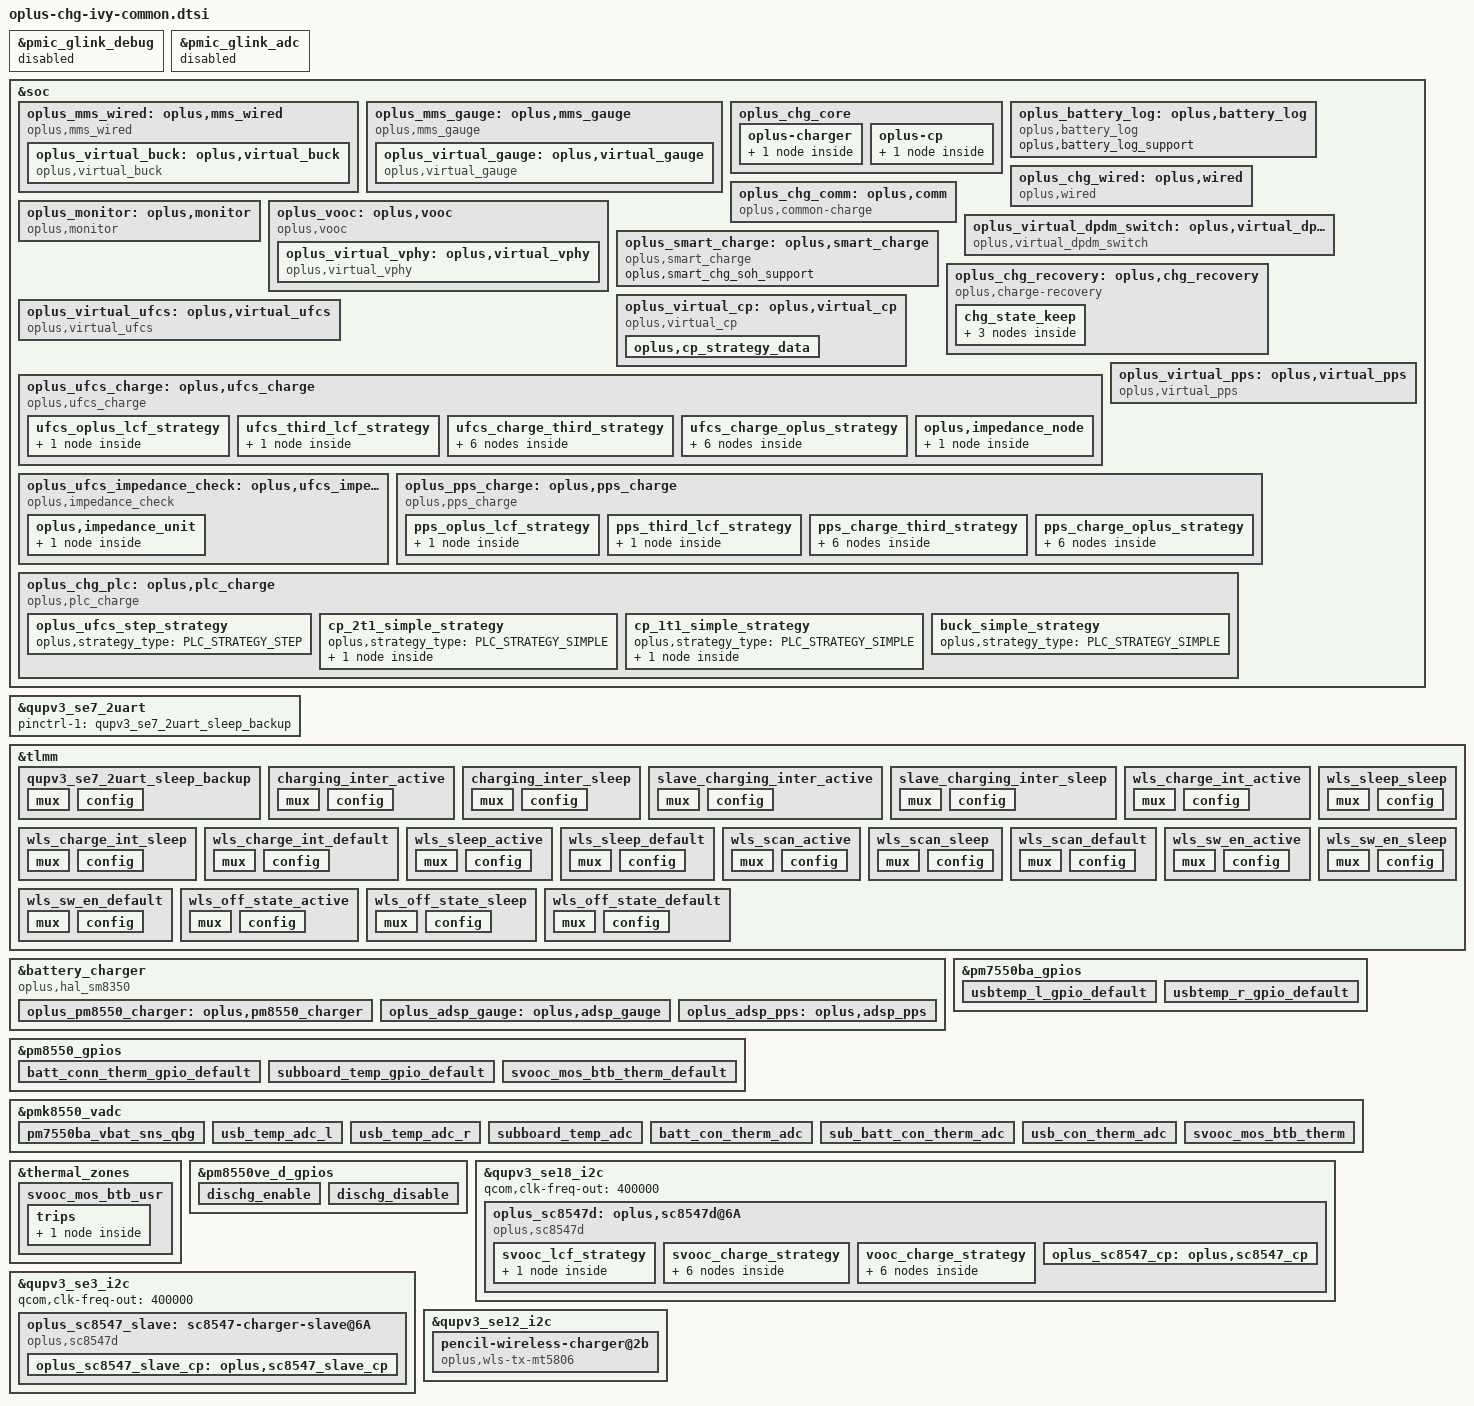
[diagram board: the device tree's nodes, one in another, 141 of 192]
//ifdef OPLUS_FEATURE_CHG_BASIC
//BSP.CHG.Basic, 2023/04/19, sjc Add for charging

#include "../oplus-chg-8850.h.dtsi"

/*
 * NOTICE:
 * sector 1: wired charging
 * sector 2: ufcs
 */

&pmic_glink_debug {
	status = "disabled";
};

&pmic_glink_adc {
	status = "disabled";
};

//#ifdef OPLUS_FEATURE_CHG_BASIC /* BSP.CHG.Basic, 2023/04/19, sjc Add for wired charging */
//for wired charging config
&soc {
	oplus_mms_wired: oplus,mms_wired {
		compatible = "oplus,mms_wired";
		oplus,buck_ic = <&oplus_virtual_buck>;

		oplus,adc_info_name = "855";

		/* BSP.CHG.Basic, 2024/09/27, Add for:
		High temperature long-term solution for Battery bulge from MTK*/
		high-temp-scheme;

		oplus,support_adjust_reverse_chg_cur;
		oplus,support_usbtemp_protect_v2;
		oplus_spec,usbtemp_batt_temp_low = <50>;
		oplus_spec,usbtemp_batt_temp_high = <50>;
		oplus_spec,usbtemp_batt_temp_over_hot = <60>;
		oplus_spec,usbtemp_ntc_temp_low = <57>;
		oplus_spec,usbtemp_ntc_temp_high = <69>;
		oplus_spec,usbtemp_temp_gap_low_with_batt_temp = <7>;
		oplus_spec,usbtemp_temp_gap_with_batt_temp_in_over_hot = <15>;
		oplus_spec,usbtemp_temp_gap_high_with_batt_temp = <12>;
		oplus_spec,usbtemp_temp_gap_low_without_batt_temp = <12>;
		oplus_spec,usbtemp_temp_gap_high_without_batt_temp = <24>;
		oplus_spec.usbtemp_rise_fast_temp_low = <3>;
		oplus_spec.usbtemp_rise_fast_temp_high = <3>;
		oplus_spec.usbtemp_rise_fast_temp_count_low = <30>;
		oplus_spec.usbtemp_rise_fast_temp_count_high = <20>;
		oplus_spec,usbtemp_cool_down_ntc_low = <54>;
		oplus_spec,usbtemp_cool_down_ntc_high = <65>;
		oplus_spec,usbtemp_cool_down_gap_low = <12>;
		oplus_spec,usbtemp_cool_down_gap_high = <20>;
		oplus_spec,usbtemp_cool_down_recover_ntc_low = <48>;
		oplus_spec,usbtemp_cool_down_recover_ntc_high = <60>;
		oplus_spec,usbtemp_cool_down_recover_gap_low = <6>;
		oplus_spec,usbtemp_cool_down_recover_gap_high = <15>;
		oplus_spec,otg_output = <2000 3600
					 1500 2900>;

		oplus_virtual_buck: oplus,virtual_buck {
			compatible = "oplus,virtual_buck";
			oplus,buck_ic = <&oplus_pm8550_charger>;
			oplus,buck_ic_index = <0>;
			oplus,buck_ic_connect = <OPLUS_CHG_IC_CONNECT_PARALLEL>;
			oplus,main_charger = <0>;
			oplus,buck_ic_current_ratio = <100>;
			oplus,buck_ic_func_group = <&plat_pm8550_groups>;

			oplus,ic_type = <OPLUS_CHG_IC_VIRTUAL_BUCK>;
			oplus,ic_index = <0>;

			oplus,dischg-gpio = <&pm8550ve_d_gpios 5 0x00>;
			oplus,usbtemp_conversion_ratio = <10>;

			pinctrl-names = "usbtemp_l_gpio_default", "usbtemp_r_gpio_default",
						"dischg_enable", "dischg_disable";
			pinctrl-0 = <&usbtemp_l_gpio_default>;
			pinctrl-1 = <&usbtemp_r_gpio_default>;
			pinctrl-2 = <&dischg_enable>;
			pinctrl-3 = <&dischg_disable>;

			io-channels = <&pmk8550_vadc PM7550BA_ADC5_GEN3_AMUX2_GPIO2_100K_PU>,
					<&pmk8550_vadc PM7550BA_ADC5_GEN3_AMUX_THM6_GPIO6_100K_PU>;
			io-channel-names = "usb_temp_adc_l", "usb_temp_adc_r";

			oplus,uart_tx-gpio = <&tlmm 62 0x00>;
			oplus,uart_rx-gpio = <&tlmm 63 0x00>;
		};
	};

	oplus_mms_gauge: oplus,mms_gauge {
		compatible = "oplus,mms_gauge";
		oplus,gauge_ic = <&oplus_virtual_gauge>;
		oplus,topic-update-interval = <5000>;
		oplus,support_subboard_ntc;
		oplus,fcl_support;
		oplus,fcl_index = <1>;	/* Platform gauge */
		oplus,vb_offset = <20>;
		oplus,voocphy_ic = <&oplus_virtual_vphy>;

		oplus_virtual_gauge: oplus,virtual_gauge {
			compatible = "oplus,virtual_gauge";
			oplus,batt_capacity_mah = <8000>;
			oplus,ic_type = <OPLUS_CHG_IC_VIRTUAL_GAUGE>;
			oplus,ic_index = <0>;
		};
	};
};

&soc {
	oplus_chg_core: oplus_chg_core {
		oplus,chg_framework_v2;
		oplus,battery_type_by_smem;
		oplus,smart_charging_screenoff;
		oplus,chg_spec_version = <OPLUS_CHG_SPEC_VER_V3P7>;
		oplus,common-charge-icl-support;
		oplus,boot_reset_adapter_support;

		oplus-charger {
			plat_pm8550_groups: oplus,plat_pm8550-groups {
				functions = <
					OPLUS_IC_FUNC_INIT
					OPLUS_IC_FUNC_EXIT
					OPLUS_IC_FUNC_REG_DUMP
					OPLUS_IC_FUNC_SMT_TEST
					OPLUS_IC_FUNC_BUCK_INPUT_PRESENT
					OPLUS_IC_FUNC_BUCK_INPUT_SUSPEND
					OPLUS_IC_FUNC_BUCK_INPUT_IS_SUSPEND
					OPLUS_IC_FUNC_BUCK_OUTPUT_SUSPEND
					OPLUS_IC_FUNC_BUCK_OUTPUT_IS_SUSPEND
					OPLUS_IC_FUNC_BUCK_GET_CC_ORIENTATION
					OPLUS_IC_FUNC_BUCK_GET_CHARGER_TYPE
					OPLUS_IC_FUNC_BUCK_RERUN_BC12
					OPLUS_IC_FUNC_BUCK_QC_DETECT_ENABLE
					OPLUS_IC_FUNC_BUCK_SHIPMODE_ENABLE
					OPLUS_IC_FUNC_BUCK_SET_QC_CONFIG
					OPLUS_IC_FUNC_BUCK_SET_PD_CONFIG
					OPLUS_IC_FUNC_GET_SHUTDOWN_SOC
					OPLUS_IC_FUNC_BACKUP_SOC
					OPLUS_IC_FUNC_GET_TYPEC_MODE
					OPLUS_IC_FUNC_BUCK_SET_ICL
					OPLUS_IC_FUNC_BUCK_GET_ICL
					OPLUS_IC_FUNC_BUCK_SET_FCC
					OPLUS_IC_FUNC_BUCK_SET_FV
					OPLUS_IC_FUNC_BUCK_SET_ITERM
					OPLUS_IC_FUNC_BUCK_SET_RECHG_VOL
					OPLUS_IC_FUNC_BUCK_GET_INPUT_CURR
					OPLUS_IC_FUNC_BUCK_GET_INPUT_VOL
					OPLUS_IC_FUNC_GET_CHARGER_CYCLE
					OPLUS_IC_FUNC_OTG_BOOST_ENABLE
					OPLUS_IC_FUNC_SET_OTG_BOOST_CURR_LIMIT
					OPLUS_IC_FUNC_BUCK_GET_VBUS_COLLAPSE_STATUS
					OPLUS_IC_FUNC_GET_OTG_ENABLE
					OPLUS_IC_FUNC_SET_OTG_SWITCH_STATUS
					OPLUS_IC_FUNC_GET_OTG_SWITCH_STATUS
					OPLUS_IC_FUNC_GET_OTG_ONLINE_STATUS
					OPLUS_IC_FUNC_BUCK_GET_HW_DETECT
					OPLUS_IC_FUNC_VOOCPHY_SET_MATCH_TEMP
					OPLUS_IC_FUNC_IS_OPLUS_SVID
					OPLUS_IC_FUNC_BUCK_SET_VINDPM
					OPLUS_IC_FUNC_WLS_BOOST_ENABLE
					OPLUS_IC_FUNC_SET_WLS_BOOST_VOL
					OPLUS_IC_FUNC_SET_WLS_BOOST_CURR_LIMIT
					OPLUS_IC_FUNC_BUCK_WLS_INPUT_SUSPEND
					OPLUS_IC_FUNC_BUCK_SET_WLS_ICL
					OPLUS_IC_FUNC_BUCK_GET_WLS_ICL
					OPLUS_IC_FUNC_BUCK_GET_WLS_INPUT_CURR
					OPLUS_IC_FUNC_BUCK_GET_WLS_INPUT_VOL
					OPLUS_IC_FUNC_BUCK_WLS_AICL_ENABLE
					OPLUS_IC_FUNC_BUCK_WLS_AICL_RERUN
					OPLUS_IC_FUNC_BUCK_DIS_INSERT_DETECT
					OPLUS_IC_FUNC_GET_TYPEC_ROLE
					OPLUS_IC_FUNC_SET_TYPEC_MODE
					OPLUS_IC_FUNC_BUCK_GET_USB_BTB_TEMP
					OPLUS_IC_FUNC_BUCK_GET_BATT_BTB_TEMP
					OPLUS_IC_FUNC_BUCK_GET_TYPEC_STATE
					OPLUS_IC_FUNC_BUCK_SET_CHG_PATH
					OPLUS_IC_FUNC_BUCK_GET_CHG_PATH_STATUS
					OPLUS_IC_FUNC_BUCK_GET_USB_AICL_ENHANCE
					OPLUS_IC_FUNC_BUCK_SET_AICL_POINT
					OPLUS_IC_FUNC_BUCK_GET_POWER_ROLE
					OPLUS_IC_FUNC_BUCK_ITEM_CHECK
					OPLUS_IC_FUNC_BUCK_GET_CC_STATE
				>;
				virqs = <
					OPLUS_IC_VIRQ_ERR
					OPLUS_IC_VIRQ_CC_DETECT
					OPLUS_IC_VIRQ_PLUGIN
					OPLUS_IC_VIRQ_CC_CHANGED
					OPLUS_IC_VIRQ_SUSPEND_CHECK
					OPLUS_IC_VIRQ_CHG_TYPE_CHANGE
					OPLUS_IC_VIRQ_OTG_ENABLE
					OPLUS_IC_VIRQ_SVID
					OPLUS_IC_VIRQ_TYPEC_STATE
					OPLUS_IC_VIRQ_POWER_ROLE_STATE
				>;
			};
		};

		oplus-cp {
			sc8547_cp_groups: oplus,cp_groups {
				functions = <
					OPLUS_IC_FUNC_INIT
					OPLUS_IC_FUNC_EXIT
					OPLUS_IC_FUNC_REG_DUMP
					OPLUS_IC_FUNC_SMT_TEST
					OPLUS_IC_FUNC_CP_ENABLE
					OPLUS_IC_FUNC_CP_HW_INTI
					OPLUS_IC_FUNC_CP_SET_WORK_MODE
					OPLUS_IC_FUNC_CP_GET_WORK_MODE
					OPLUS_IC_FUNC_CP_CHECK_WORK_MODE_SUPPORT
					OPLUS_IC_FUNC_CP_SET_IIN
					OPLUS_IC_FUNC_CP_GET_VIN
					OPLUS_IC_FUNC_CP_GET_IIN
					OPLUS_IC_FUNC_CP_GET_VOUT
					OPLUS_IC_FUNC_CP_GET_IOUT
					OPLUS_IC_FUNC_CP_GET_VAC
					OPLUS_IC_FUNC_CP_SET_WORK_START
					OPLUS_IC_FUNC_CP_GET_WORK_STATUS
					OPLUS_IC_FUNC_CP_SET_ADC_ENABLE
					OPLUS_IC_FUNC_CP_WATCHDOG_ENABLE
					OPLUS_IC_FUNC_CP_SET_UCP_DISABLE
					OPLUS_IC_FUNC_CP_GET_IIN_MAX
					OPLUS_IC_FUNC_CP_WATCHDOG_RESET
					OPLUS_IC_FUNC_CP_SET_SSTIMEOUT_UCP_ENABLE
				>;
				virqs = <
					OPLUS_IC_VIRQ_ERR
					OPLUS_IC_VIRQ_ONLINE
					OPLUS_IC_VIRQ_OFFLINE
				>;
			};
		};
	};
};

&qupv3_se7_2uart {
	pinctrl-1 = <&qupv3_se7_2uart_sleep_backup>;
	status = "okay";
};

&tlmm {
	qupv3_se7_2uart_sleep_backup:qupv3_se7_2uart_sleep_backup {
		mux {
			pins = "gpio62", "gpio63";
			function = "gpio";
		};

		config {
			pins = "gpio62", "gpio63";
			drive-strength = <2>;
			bias-disable;
			input-enable;
		};
	};

	charging_inter_active: charging_inter_active {
		mux {
			pins = "gpio61";
			function = "gpio";
		};
		config {
			pins = "gpio61";
			bias-pull-up;
			drive-strength = <2>;
			input-enable;
		};
	};

	charging_inter_sleep: charging_inter_sleep {
		mux {
			pins = "gpio61";
			function = "gpio";
		};
		config {
			pins = "gpio61";
			bias-pull-up;
			drive-strength = <2>;
			input-enable;
		};
	};

	slave_charging_inter_active: slave_charging_inter_active {
		mux {
			pins = "gpio28";
			function = "gpio";
		};
		config {
			pins = "gpio28";
			bias-pull-up;
			drive-strength = <2>;
			input-enable;
		};
	};

	slave_charging_inter_sleep: slave_charging_inter_sleep {
		mux {
			pins = "gpio28";
			function = "gpio";
		};
		config {
			pins = "gpio28";
			bias-pull-up;
			drive-strength = <2>;
			input-enable;
		};
	};
};

&battery_charger {
	compatible = "oplus,hal_sm8350";
	oplus,chg_ops = "plat-pmic";

	qcom,pmic_ftm_vph = "/sys/bus/spmi/drivers/pmic-spmi/0-00/c426000.spmi:pmk8850@0:vadc@9000/iio:device0/in_voltage_pmih010x_vph2_pwr_input";
	qcom,pmic_ftm_vbat = "/sys/bus/spmi/drivers/pmic-spmi/0-00/c426000.spmi:pmk8850@0:vadc@9000/iio:device0/in_voltage_pmih010x_vbat_sns_qbg_input";

	pinctrl-names = "default", "subboard_temp_gpio_default";
	pinctrl-0 = <&svooc_mos_btb_therm_default>,
			<&batt_conn_therm_gpio_default>;
	pinctrl-1 = <&subboard_temp_gpio_default>;

	oplus,usb_aicl_enhance;
	oplus,voocphy_support;
	oplus,vooc_project = <14>;
	oplus,batt_num = <1>;
	oplus,otg_scheme = <0>;//0:cid 1:ccdetect_gpio 2:switch
	oplus,ufcs_run_check_support;
	oplus,soccp_support;
	io-channels	= <&pmk8550_vadc PM8550_ADC5_GEN3_AMUX2_GPIO4_100K_PU>,
			  <&pmk8550_vadc PM8550_ADC5_GEN3_AMUX_THM6_GPIO2_100K_PU>,
			  <&pmk8550_vadc PM7550BA_ADC5_GEN3_AMUX_THM4_USB_THERM_100K_PU>,
			  <&pmk8550_vadc PM7550BA_ADC5_GEN3_VPH_PWR>,
			  <&pmk8550_vadc PM7550BA_ADC5_GEN3_VBAT_SNS_QBG>;
	io-channel-names = "subboard_temp_adc",
			   "batt_con_therm_adc",
			   "usb_con_therm_adc",
			   "vph_pwr",
			   "vbat_sns_qbg";

	oplus_pm8550_charger: oplus,pm8550_charger {
		oplus,ic_type = <OPLUS_CHG_IC_BUCK>;
		oplus,ic_index = <0>;
	};
	oplus_adsp_gauge: oplus,adsp_gauge {
		oplus,ic_type = <OPLUS_CHG_IC_GAUGE>;
		oplus,ic_index = <0>;
		oplus,ic_devinfo = "QBG","Qcom";
	};
	oplus_adsp_pps: oplus,adsp_pps {
		oplus,ic_type = <OPLUS_CHG_IC_PPS>;
		oplus,ic_index = <0>;
	};
};

&soc {
	oplus_battery_log: oplus,battery_log {
		compatible = "oplus,battery_log";
		oplus,battery_log_support;
	};

	oplus_chg_wired: oplus,wired {
		compatible = "oplus,wired";

		oplus,vooc-support;
		oplus,qc-curr-check-support;
		oplus_spec,vbatt_pdqc_to_5v_thr = <4500>;
		oplus_spec,vbatt_pdqc_to_9v_thr = <4500>;
		oplus_spec,pd-iclmax-ma = <2000>;
		oplus_spec,qc-iclmax-ma = <2000>;
		oplus_spec,non-standard-ibatmax-ma = <500>;
		oplus_spec,input-power-mw = <
			2500		/* OPLUS_WIRED_CHG_MODE_UNKNOWN */
			2500		/* OPLUS_WIRED_CHG_MODE_SDP */
			7500		/* OPLUS_WIRED_CHG_MODE_CDP */
			10000		/* OPLUS_WIRED_CHG_MODE_DCP */
			30000		/* OPLUS_WIRED_CHG_MODE_VOOC */
			13500		/* OPLUS_WIRED_CHG_MODE_QC */
			13500		/* OPLUS_WIRED_CHG_MODE_PD */
		>;
		oplus_spec,led_on-fccmax-ma = <0 1173 3300 3300 3300 3300 3300 1000 0>;
		oplus_spec,fccmax-ma-lv = <
			0 1173 2200 2200 2200 2200 2200 2200 0	/* OPLUS_WIRED_CHG_MODE_UNKNOWN */
			0 600 600  600  600  600  600  600 0	/* OPLUS_WIRED_CHG_MODE_SDP */
			0 1173 1600 1600 1600 1600 1600 1600 0	/* OPLUS_WIRED_CHG_MODE_CDP */
			0 1173 2200 2200 2200 2200 2200 2200 0	/* OPLUS_WIRED_CHG_MODE_DCP */
			0 1173 3300 3300 3300 3300 3300 3300 0	/* OPLUS_WIRED_CHG_MODE_VOOC */
			0 1173 3300 3300 3300 3300 3300 3300 0	/* OPLUS_WIRED_CHG_MODE_QC */
			0 1173 3300 3300 3300 3300 3300 3300 0	/* OPLUS_WIRED_CHG_MODE_PD */
		>;
		oplus_spec,fccmax-ma-hv = <
			0 1173 2200 2200 2200 2200 2200 2200 0	/* OPLUS_WIRED_CHG_MODE_UNKNOWN */
			0 600  600  600  600  600  600  600 0	/* OPLUS_WIRED_CHG_MODE_SDP */
			0 1173 1600 1600 1600 1600 1600 1600 0	/* OPLUS_WIRED_CHG_MODE_CDP */
			0 1173 2200 2200 2200 2200 2200 2200 0	/* OPLUS_WIRED_CHG_MODE_DCP */
			0 1173 3300 3300 3300 3300 3300 3300 0	/* OPLUS_WIRED_CHG_MODE_VOOC */
			0 1173 3300 3300 3300 3300 3300 3300 0	/* OPLUS_WIRED_CHG_MODE_QC */
			0 1173 3300 3300 3300 3300 3300 3300 0	/* OPLUS_WIRED_CHG_MODE_PD */
		>;

		oplus_spec,cool_down_sale_pdqc_vol_mv = <5000>;
		oplus_spec,cool_down_sale_pdqc_curr_ma = <1200>;
		oplus_spec,cool_down_pdqc_vol_mv = <5000 5000 5000 9000>;
		oplus_spec,cool_down_pdqc_curr_ma = <1200 1500 2000 1500>;
		oplus_spec,cool_down_vooc_curr_ma = <1200 1500 2000 2500 3000 3000>;
		oplus_spec,cool_down_normal_curr_ma = <1200 1500 2000>;

		oplus_spec,vbus_ov_thr_mv = <11000 11000>;
		oplus_spec,vbus_uv_thr_mv = <4300 4300>;

		/* first data is strategy used temp type */
		oplus,vooc_strategy_name = "cgcl";
		oplus,vooc_strategy_data = <OPLUS_STRATEGY_USE_BATT_TEMP
					    0   420 6000 1 0
					    415 430 3000 2 0
					    425 440 2000 2 1>;
	};

	oplus_chg_comm: oplus,comm {
		compatible = "oplus,common-charge";
		oplus_spec,dec_step = <20>;
		oplus_spec,dec-vol-cc-full-thr = <0 200 400 600 800 1000>;
		oplus_spec,dec-vol-fv-full-mv = <0 0 20 20 40 40>;

		oplus_spec,batt-them-thr = <(-100) 0 50 120 160 350 450 530>;
		oplus_spec,iterm-ma = <401>;
		oplus_spec,fv-mv = <4490 4490 4490 4490 4490 4490 4470 4130 4130>;
		oplus_spec,sw-fv-mv = <4440 4440 4440 4440 4440 4440 4420 4080 4080>;
		oplus_spec,hw-fv-inc-mv = <0 18 18 18 18 18 18 18 0>;
		oplus_spec,sw-over-fv-mv = <4500 4500 4500 4500 4500 4500 4480 4140 4140>;
		oplus_spec,sw-over-fv-dec-mv = <8>;
		oplus_spec,non-standard-sw-fv-mv = <3930>;
		oplus_spec,non-standard-fv-mv = <3980>;
		oplus_spec,non-standard-hw-fv-inc-mv = <18>;
		oplus_spec,non-standard-sw-over-fv-mv = <3990>;
		oplus_spec,non-standard-vbatdet-mv = <3680>;
		oplus_spec,wired-vbatdet-mv = <0 4190 4290 4390 4390 4390 4370 4030 0>;
		oplus_spec,wls-vbatdet-mv = <0 4190 4290 4390 4390 4390 4370 4030 0>;
		oplus_spec,fcc-gear-thr-mv = <4180>;
		oplus_spec,fcc-gear-shake-mv = <400 400 400 300 300 180 180 180 180>;
		oplus_spec,vbatt-ov-thr-mv = <4600>;
		oplus_spec,full_pre_ffc_judge;
		oplus_spec,full-pre-ffc-mv = <4485>;
		oplus_spec,ffc-temp-thr = <120 210 350 440>;
		oplus_spec,wired-ffc-step-max = <2>;
		oplus_spec,wired-ffc-fv-mv = <4630 4630>;

		oplus_spec,wired-ffc-fv-cutoff-mv = <4545 4545 4500
						     4545 4545 4483>;

		oplus_spec,removed_bat_decidegc = <390>;

		oplus_spec,wired-ffc-fcc-ma = <2076 2076 1500
					       1976  1976  1000>;
		oplus_spec,wired-ffc-fcc-cutoff-ma = <1876 1876 1300
						      1776 1776 900>;

		oplus_spec,drop_soc_2_temp_ladder = <(-50) 0 0 0 0 0 0 0 0 0>;
		oplus_spec,volt_diff_ladder_of_drop_soc_2 = <80 80 0 0 0 0 0 0 0 0>;
		oplus_spec,keep_soc_2_temp_ladder = <(-200) (-50) 0 0 0 0 0 0 0 0>;
		oplus_spec,volt_diff_ladder_of_keep_soc_2 = <10 20 30 0 0 0 0 0 0 0>;
		oplus_spec,back_rm_of_drop_soc_2 = <36>;
		oplus_spec,back_rm_of_drop_soc_1 = <0>;
		oplus_spec,load_current_of_drop_soc_2 = <1500>;
		oplus_spec,load_current_of_drop_soc_1 = <2000>;
		oplus_spec,current_limit_of_drop_soc_2 = <350>;
		oplus_spec,volt_of_fast_drop_soc_1 = <3300>;
		oplus_spec,support_uisoc_low_battery_control;

		oplus_spec,vbat_uv_thr_mv = <3300>;
		oplus_spec,vbat_charging_uv_thr_mv = <3200>;

		/*If use subboard NTC as battery temp, config it as 20, otherwise 0 */
		oplus_spec,tbatt_power_off_cali_temp = <0>;
		oplus,vooc_show_ui_soc_decimal;
		oplus_spec,poweroff_high_batt_temp = <720>;
		oplus_spec,poweroff_emergency_batt_temp = <770>;
		oplus,ui_soc_decimal_speedmin = <20>;

		oplus,gauge_stuck_jump_support;
		oplus,gauge_stuck_threshold = <15>;
		oplus,gauge_stuck_time = <50>;

		oplus,ui_soc_2_voltage_comp_mv = <30>;
		oplus,chg_shutdown_max_mv = <3200>;

		oplus_spec,hw_iterm_support;
		oplus,pm_power_off_with_hightemp;
	};

	oplus_monitor: oplus,monitor {
		compatible = "oplus,monitor";
		oplus,topic-update-interval = <60000>;

		track,fast_chg_break_t_thd = <2500>;
		track,general_chg_break_t_thd = <300>;
		track,voocphy_type = <TRACK_AP_DUAL_CP_VOOCPHY>;
		track,wired_max_power = <67000>;
		track,wired_fast_chg_scheme = <TRACK_WIRED_SCHEME_SINGLE_60W_67W>;
		track,track_ver = <TRACK_VER_4_0>;
	};

	oplus_vooc: oplus,vooc {
		compatible = "oplus,vooc";
		oplus,vooc_ic = <&oplus_virtual_vphy>;

		oplus,vooc_data_width = <7>;
		oplus,vooc_curr_max = <CP_CURR_LIMIT_7BIT_12_6A>;
		oplus,vooc_project = <VOOC_PROJECT_11V6P1A_SINGLE_BAT_SVOOC>;
		oplus,vooc_curr_table_type = <VOOC_CP_CURR_TABLE>;
		oplus,vooc_power_max_w = <67>;
		oplus,voocphy_support = <AP_DUAL_CP_VOOCPHY>;
		oplus,subboard_ntc_abnormal_current = <4000>;
		oplus,support_fake_vooc_check;
		oplus,cp_cooldown_limit_percent_75 = <CP_CURR_LIMIT_7BIT_6_0A>;
		oplus,cp_cooldown_limit_percent_85 = <CP_CURR_LIMIT_7BIT_4_0A>;

		oplus,general_strategy_name = "cgcl";
		oplus,general_strategy_data = < OPLUS_STRATEGY_USE_SHELL_TEMP
						0   380 CP_CURR_LIMIT_7BIT_12_6A 1 0
						370 400 CP_CURR_LIMIT_7BIT_7_0A 2 0
						390 420 CP_CURR_LIMIT_7BIT_5_0A 3 1
						410 430 CP_CURR_LIMIT_7BIT_4_0A 4 2
						420 440 CP_CURR_LIMIT_7BIT_3_0A 4 3 >;
		oplus,plc_strategy-data = <&buck_simple_strategy &cp_2t1_simple_strategy &cp_1t1_simple_strategy>;
		oplus,plc_strategy-names = "default", "svooc", "vooc";

		oplus_virtual_vphy: oplus,virtual_vphy {
			compatible = "oplus,virtual_vphy";
			oplus,vphy_ic = <&oplus_sc8547d>;
			oplus,dpdm_switch_ic = <&oplus_virtual_dpdm_switch>;

			oplus,ic_type = <OPLUS_CHG_IC_VIRTUAL_VPHY>;
			oplus,ic_index = <0>;
		};
	};

	oplus_virtual_dpdm_switch: oplus,virtual_dpdm_switch {
		compatible = "oplus,virtual_dpdm_switch";
		oplus,ic_type = <OPLUS_CHG_IC_MISC>;
		oplus,ic_index = <0>;
		oplus,use_audio_switch;
	};

	oplus_smart_charge: oplus,smart_charge {
		compatible = "oplus,smart_charge";
		oplus,smart_chg_soh_support;
	};

	oplus_chg_recovery: oplus,chg_recovery {
		compatible = "oplus,charge-recovery";

		chg_state_keep {
			wired_disconnect_detection {
				protocol_switch_table = <
					CHG_PROTOCOL_UFCS  44  3  3
					CHG_PROTOCOL_PPS    0  3  3
					CHG_PROTOCOL_VOOC   0  0  0
					CHG_PROTOCOL_PD     0  3  3
					CHG_PROTOCOL_QC     0  3  3
					CHG_PROTOCOL_BC12   0  3  3
				>;
			};
			vooc_disconnect_detection {};
			dcp_disconnect_detection {};
		};
	};
};

&pm7550ba_gpios {
	usbtemp_l_gpio_default: usbtemp_l_gpio_default {
		pins = "gpio6"; //GPIO 6
		function = "normal"; //normal
		bias-high-impedance; //DISABLE for ADC
		bias-disable;
	};
	usbtemp_r_gpio_default: usbtemp_r_gpio_default {
		pins = "gpio18"; //GPIO 18
		function = "normal"; //normal
		bias-high-impedance; //DISABLE for ADC
		bias-disable;
	};
};

&pm8550_gpios {
	batt_conn_therm_gpio_default: batt_conn_therm_gpio_default {
		pins = "gpio2";
		function = "normal";
		bias-high-impedance;
		bias-disable;
		output-disable;
	};

	subboard_temp_gpio_default: subboard_temp_gpio_default {
		pins = "gpio4";
		function = "normal";
		bias-high-impedance;
		bias-disable;
	};

	svooc_mos_btb_therm_default: svooc_mos_btb_therm_default {
		pins = "gpio7";
		function = "normal";
		bias-high-impedance;
		bias-disable;
	};
};

&pmk8550_vadc {
	pm7550ba_vbat_sns_qbg {
		reg = <PM7550BA_ADC5_GEN3_VBAT_SNS_QBG>;
		label = "pm7550ba_vbat_sns_qbg";
		qcom,pre-scaling = <1 3>;
	};

	usb_temp_adc_l {
		reg = <PM7550BA_ADC5_GEN3_AMUX2_GPIO2_100K_PU>;
		label = "usb_temp_adc_l";
		qcom,pre-scaling = <1 1>;
		qcom,hw-settle-time = <200>;
		qcom,scale-fn-type = <OPLUS_ADC_SCALE_HW_CALIB_DEFAULT>;
	};

	/delete-node/ pm7550ba_sys_therm_4;

	usb_temp_adc_r {
		reg = <PM7550BA_ADC5_GEN3_AMUX_THM6_GPIO6_100K_PU>;
		label = "usb_temp_adc_r";
		qcom,pre-scaling = <1 1>;
		qcom,hw-settle-time = <200>;
		qcom,scale-fn-type = <OPLUS_ADC_SCALE_HW_CALIB_DEFAULT>;
	};

	subboard_temp_adc {
		reg = <PM8550_ADC5_GEN3_AMUX2_GPIO4_100K_PU>;
		label = "subboard_temp_adc";
		qcom,pre-scaling = <1 1>;
		qcom,ratiometric;
		qcom,hw-settle-time = <200>;
	};

	batt_con_therm_adc {
		reg = <PM8550_ADC5_GEN3_AMUX_THM6_GPIO2_100K_PU>;
		label = "batt_con_therm_adc";
		qcom,ratiometric;
		qcom,hw-settle-time = <200>;
		qcom,pre-scaling = <1 1>;
	};

	sub_batt_con_therm_adc {
		reg = <PMK8550_ADC5_GEN3_AMUX_THM4_GPIO3_100K_PU>;
		label = "sub_batt_con_therm_adc";
		qcom,ratiometric;
		qcom,hw-settle-time = <200>;
		qcom,pre-scaling = <1 1>;
		qcom,adc-tm-type = <0>;
	};

	usb_con_therm_adc {
		reg = <PM7550BA_ADC5_GEN3_AMUX_THM4_USB_THERM_100K_PU>;
		label = "usb_con_therm_adc";
		qcom,ratiometric;
		qcom,hw-settle-time = <200>;
		qcom,pre-scaling = <1 1>;
	};

	svooc_mos_btb_therm {
		reg = <PM8550_ADC5_GEN3_AMUX3_GPIO7_100K_PU>;
		label = "svooc_mos_btb_therm";
		qcom,ratiometric;
		qcom,hw-settle-time = <200>;
		qcom,pre-scaling = <1 1>;
		qcom,adc-tm-type = <1>;
	};
};

&thermal_zones {
	/delete-node/ sys-therm-4;

	svooc_mos_btb_usr {
		polling-delay-passive = <0>;
		polling-delay = <0>;
		thermal-governor = "user_space";
		thermal-sensors = <&pmk8550_vadc PM8550_ADC5_GEN3_AMUX3_GPIO7_100K_PU>;
		wake-capable-sensor;
		trips {
			active-config0 {
				temperature = <125000>;
				hysteresis = <1000>;
				type = "passive";
			};
		};
	};
};

&pm8550ve_d_gpios {
	dischg_enable: dischg_enable {
		pins = "gpio5";
		function = "normal";
		bias-disable;
		power-source = <0>;
		output-high;
		qcom,drive-strength = <3>;
	};
	dischg_disable: dischg_disable {
		pins = "gpio5";
		function = "normal";
		bias-disable;
		power-source = <0>;
		output-low;
		qcom,drive-strength = <3>;
	};
};

&qupv3_se18_i2c {
	status = "okay";
	qcom,clk-freq-out = <400000>;

	oplus_sc8547d: oplus,sc8547d@6A {
		status = "okay";
		compatible = "oplus,sc8547d";
		reg = <0x6A>;
		oplus,use_vooc_phy;
		oplus,use_ufcs_phy;
		oplus,vac_support;
		oplus,always_otg_en;

		oplus_spec,irq_gpio = <&tlmm 61 0x00>;

		pinctrl-names = "charging_inter_active", "charging_inter_sleep";
		pinctrl-0 = <&charging_inter_active>;
		pinctrl-1 = <&charging_inter_sleep>;

		oplus,ic_type = <OPLUS_CHG_IC_VPHY>;
		oplus,ic_index = <0>;
		oplus,vooc-version = <VOOC_VERSION_5_0>;

		oplus_spec,vooc_bad_volt = <3450 3400 3350 3300>;
		oplus_spec,vooc_bad_volt_suspend = <3450 3400 3350 3300>;
		oplus_spec,vooc_bad_volt_check_head_mask = /bits/ 8 <0x3>; /* VOOC 2.0/VOOC3.0 */
		oplus_spec,ap_control_allow;
		oplus_spec,voocphy_current_default = <61>;

		oplus_spec,vooc_little_cold_full_voltage = <4510>;
		oplus_spec,vooc_cool_full_voltage = <4510>;
		oplus_spec,vooc_warm_full_voltage = <4130>;
		oplus_spec,vooc_1time_full_voltage = <4560>;
		oplus_spec,vooc_ntime_full_voltage = <4550>;
		oplus_spec,full_voltage = < /* vol_1time vol_ntime */
					4520 4510 /* 0 ~ 5 */
					4520 4510 /* 5 ~ 12 */
					4560 4550 /* 12 ~ 16 */
					4560 4550 /* 16 ~ 20 */
					4560 4550 /* 20 ~ 35 */
					4560 4550 /* 35 ~ 44 */
					4140 4130 /* 44 ~ 51 */
					>;

		ocp_reg = <0xf>;
		ovp_reg = <0x36>;
		vbus_ovp_reg = /bits/ 8 <0x5A>;
		oplus_spec,voocphy_dual_cp_support;
		oplus_spec,slave_cp_enable_thr = <1400>;
		oplus_spec,slave_cp_disable_thr_high = <1100>;
		oplus_spec,impedance_calculation_newmethod;
		oplus_spec,svooc_circuit_r_l = <0xa>;
		oplus_spec,svooc_circuit_r_h = <0x1>;

		oplus_spec,vooc_multistep_initial_batt_temp = <1000>;
		oplus_spec,vooc_little_cool_temp = <160>;
		oplus_spec,vooc_little_cool_high_temp = <210>;
		oplus_spec,vooc_cool_temp = <120>;
		oplus_spec,vooc_little_cold_temp = <50>;
		oplus_spec,vooc_normal_low_temp = <350>;
		oplus_spec,vooc_normal_to_little_cool_current = <100>;
		oplus_spec,vooc_over_high_temp = <510>;
		oplus_spec,vooc_low_temp = <0>;
		oplus_spec,vooc_high_temp = <500>;
		oplus_spec,vooc_low_soc = <0>;
		oplus_spec,vooc_high_soc = <90>;
		oplus_spec,vooc_normal_high_temp = <440>;
		oplus_spec,vooc_warm_vol_thr = <4000>;
		oplus_spec,vooc_warm_soc_thr = <55>;
		oplus_spec,vooc_full_recheck_temp = <210>;

		oplus_spec,fastchg_timeout_time_init = <201080>;
		oplus_spec,voocphy_ibat_over_current = <13600>;
		oplus_spec,voocphy_cp_max_ibus = <5300>;

		oplus_spec,voocphy_req_freq = <1785600 2438400>;
		oplus_spec,voocphy_freq_mincore = <1785600>;
		oplus_spec,voocphy_freq_midcore = <2438400>;
		oplus_spec,voocphy_freq_maxcore = <2438400>;
		oplus_spec,voocphy_current_change_timeout = <100>;
		oplus_spec,copycat_vooc_support;

		oplus_spec,soc_range = <0 20 35 55 75 85 90>;

		svooc_batt_sys_curve = <0 1 1 1 1 0 1	// 6100mA
					0 0 0 0 0 0 1	// 3414mV
					0 0 1 1 0 1 0	// 2600mA
					1 1 1 1 1 1 0	// 4664mV
					0 0 0 1 0 1 1	// 1100mA
					1 1 1 1 1 1 0>;	// 4664mV

		vooc_batt_sys_curve =  <0 1 1 1 1 0 0	// 6000mA
					0 0 0 0 0 0 1	// 3414mV
					0 0 1 1 0 1 0	// 2600mA
					1 1 1 1 1 1 0	// 4664mV
					0 0 0 1 0 1 1	// 1100mA
					1 1 1 1 1 1 0>;	// 4664mV

		svooc_lcf_strategy {
			oplus,temp_type = <OPLUS_STRATEGY_USE_SHELL_TEMP>;
			oplus,temp_range = <0 50 120 160 210 380 440>;

			strategy_temp_range_curves {
				strategy_temp_range_t0 =	<400  4510 0
								 375  4500 0
								 350  4490 0
								 325  4480 0
								 300  4470 1>;
				strategy_temp_range_t1 =	<400  4510 0
								 365  4505 0
								 330  4490 0
								 295  4480 0
								 260  4470 1>;
				strategy_temp_range_t2 =	<1009 4550 0
								 959 4545 0
								 859 4530 0
								 759  4520 0
								 609  4510 1>;
				strategy_temp_range_t3 =	<1926 4550 0
								 1876 4545 0
								 1776 4530 0
								 1676 4520 0
								 1526 4510 1>;
				strategy_temp_range_t4 =	<1926 4550 0
								 1876 4545 0
								 1776 4530 0
								 1676 4520 0
								 1526 4510 1>;
				strategy_temp_range_t5 =	<2554 4546 0
								 2354 4543 0
								 1904 4505 0
								 1454 4488 0
								 1000 4471 1>;
			};
		};

		svooc_charge_strategy {
			strategy_soc_0_to_50 { /* 0 ~ 20 */
				strategy_temp_little_cold =	<4150 17 0 0 0
								 4150 15 0 0 0
								 4510 10 1 0 0>;
				strategy_temp_cool =		<4150 29 0 0 0
								 4150 25 0 0 0
								 4150 20 0 0 0
								 4500 17 0 0 0
								 4500 15 0 0 0
								 4510 10 1 0 0>;
				strategy_temp_little_cool =	<4150 37 0 0 0
								 4150 35 0 0 0
								 4150 30 0 0 0
								 4230 29 0 0 0
								 4230 25 0 0 0
								 4230 20 0 0 0
								 4540 17 0 0 0
								 4540 15 0 0 0
								 4550 10 1 0 0>;
				strategy_temp_little_cool_high = <4150 61 0 0 0
								 4150 60 0 0 0
								 4230 56 0 0 0
								 4230 55 0 0 0
								 4230 50 0 0 0
								 4510 45 0 0 0
								 4510 40 0 0 0
								 4510 35 0 0 0
								 4510 30 0 0 0
								 4540 29 0 0 0
								 4540 25 0 0 0
								 4540 20 0 0 0
								 4540 15 0 0 0
								 4550 10 1 0 0>;
				strategy_temp_normal_low =	<4150 61 0 60 0
								 4150 60 0 60 0
								 4230 56 0 120 0
								 4230 55 0 240 0
								 4230 50 0 0 0
								 4510 45 0 0 0
								 4510 40 0 0 0
								 4510 35 0 0 0
								 4510 30 0 0 0
								 4540 29 0 0 0
								 4540 25 0 0 0
								 4540 20 0 0 0
								 4540 15 0 0 0
								 4550 10 1 0 0>;
				strategy_temp_normal_high =	<4150 61 0 60 0
								 4150 60 0 60 0
								 4230 56 0 120 0
								 4230 55 0 240 0
								 4230 50 0 0 0
								 4510 45 0 0 0
								 4510 40 0 0 0
								 4510 35 0 0 0
								 4510 30 0 0 0
								 4540 29 0 0 0
								 4540 25 0 0 0
								 4540 20 0 0 0
								 4550 15 1 0 0>;
				strategy_temp_warm =		<4120 20 0 0 0
								 4120 15 0 0 0
								 4130 10 1 0 0>;
			};

			strategy_soc_0_to_50_mid { /* 21 ~ 35 */
				strategy_temp_little_cold =	<4150 17 0 0 0
								 4150 15 0 0 0
								 4510 10 1 0 0>;
				strategy_temp_cool =		<4150 29 0 0 0
								 4150 25 0 0 0
								 4150 20 0 0 0
								 4500 17 0 0 0
								 4500 15 0 0 0
								 4510 10 1 0 0>;
				strategy_temp_little_cool =	<4150 37 0 0 0
								 4150 35 0 0 0
								 4150 30 0 0 0
								 4230 29 0 0 0
								 4230 25 0 0 0
								 4230 20 0 0 0
								 4540 17 0 0 0
								 4540 15 0 0 0
								 4550 10 1 0 0>;
				strategy_temp_little_cool_high = <4150 61 0 0 0
								 4150 60 0 0 0
								 4230 56 0 0 0
								 4230 55 0 0 0
								 4230 50 0 0 0
								 4510 45 0 0 0
								 4510 40 0 0 0
								 4510 35 0 0 0
								 4510 30 0 0 0
								 4540 29 0 0 0
								 4540 25 0 0 0
								 4540 20 0 0 0
								 4540 15 0 0 0
								 4550 10 1 0 0>;
				strategy_temp_normal_low =	<4150 61 0 60 0
								 4150 60 0 60 0
								 4230 56 0 120 0
								 4230 55 0 240 0
								 4230 50 0 0 0
								 4510 45 0 0 0
								 4510 40 0 0 0
								 4510 35 0 0 0
								 4510 30 0 0 0
								 4540 29 0 0 0
								 4540 25 0 0 0
								 4540 20 0 0 0
								 4540 15 0 0 0
								 4550 10 1 0 0>;
				strategy_temp_normal_high =	<4150 61 0 60 0
								 4150 60 0 60 0
								 4230 56 0 120 0
								 4230 55 0 240 0
								 4230 50 0 0 0
								 4510 45 0 0 0
								 4510 40 0 0 0
								 4510 35 0 0 0
								 4510 30 0 0 0
								 4540 29 0 0 0
								 4540 25 0 0 0
								 4540 20 0 0 0
								 4550 15 1 0 0>;
				strategy_temp_warm =		<4120 20 0 0 0
								 4120 15 0 0 0
								 4130 10 1 0 0>;
			};

			strategy_soc_0_to_50_high { /* 36 ~ 55 */
				strategy_temp_little_cold =	<4150 17 0 0 0
								 4150 15 0 0 0
								 4510 10 1 0 0>;
				strategy_temp_cool =		<4150 25 0 0 0
								 4150 20 0 0 0
								 4500 17 0 0 0
								 4500 15 0 0 0
								 4510 10 1 0 0>;
				strategy_temp_little_cool =	<4150 37 0 0 0
								 4150 35 0 0 0
								 4150 30 0 0 0
								 4230 29 0 0 0
								 4230 25 0 0 0
								 4230 20 0 0 0
								 4540 17 0 0 0
								 4540 15 0 0 0
								 4550 10 1 0 0>;
				strategy_temp_little_cool_high = <4510 40 0 0 0
								 4510 35 0 0 0
								 4510 30 0 0 0
								 4540 29 0 0 0
								 4540 25 0 0 0
								 4540 20 0 0 0
								 4540 15 0 0 0
								 4550 10 1 0 0>;
				strategy_temp_normal_low =	<4150 61 0 60 0
								 4150 60 0 60 0
								 4230 56 0 120 0
								 4230 55 0 240 0
								 4230 50 0 0 0
								 4510 45 0 0 0
								 4510 40 0 0 0
								 4510 35 0 0 0
								 4510 30 0 0 0
								 4540 29 0 0 0
								 4540 25 0 0 0
								 4540 20 0 0 0
								 4540 15 0 0 0
								 4550 10 1 0 0>;
				strategy_temp_normal_high =	<4150 61 0 60 0
								 4150 60 0 60 0
								 4230 56 0 120 0
								 4230 55 0 240 0
								 4230 50 0 0 0
								 4510 45 0 0 0
								 4510 40 0 0 0
								 4510 35 0 0 0
								 4510 30 0 0 0
								 4540 29 0 0 0
								 4540 25 0 0 0
								 4540 20 0 0 0
								 4550 15 1 0 0>;
				strategy_temp_warm =		<4120 20 0 0 0
								 4120 15 0 0 0
								 4130 10 1 0 0>;
			};

			strategy_soc_50_to_75 { /* 56 ~ 75 */
				strategy_temp_little_cold =	<4150 15 0 0 0
								 4510 10 1 0 0>;
				strategy_temp_cool =		<4500 15 0 0 0
								 4510 10 1 0 0>;
				strategy_temp_little_cool =	<4230 25 0 0 0
								 4230 20 0 0 0
								 4540 17 0 0 0
								 4540 15 0 0 0
								 4550 10 1 0 0>;
				strategy_temp_little_cool_high = <4510 30 0 0 0
								 4540 29 0 0 0
								 4540 25 0 0 0
								 4540 20 0 0 0
								 4540 15 0 0 0
								 4550 10 1 0 0>;
				strategy_temp_normal_low =	<4510 30 0 0 0
								 4540 29 0 0 0
								 4540 25 0 0 0
								 4540 20 0 0 0
								 4540 15 0 0 0
								 4550 10 1 0 0>;
				strategy_temp_normal_high =	<4510 35 0 0 0
								 4510 30 0 0 0
								 4540 29 0 0 0
								 4540 25 0 0 0
								 4540 20 0 0 0
								 4550 15 1 0 0>;
				strategy_temp_warm =		<4130 10 1 0 0>;
			};

			strategy_soc_75_to_85 { /* 76 ~ 85 */
				strategy_temp_little_cold =	<4510 10 1 0 0>;
				strategy_temp_cool =		<4500 15 0 0 0
								 4510 10 1 0 0>;
				strategy_temp_little_cool =	<4230 20 0 0 0
								 4540 17 0 0 0
								 4540 15 0 0 0
								 4550 10 1 0 0>;
				strategy_temp_little_cool_high = <4540 25 0 0 0
								 4540 20 0 0 0
								 4540 15 0 0 0
								 4550 10 1 0 0>;
				strategy_temp_normal_low =	<4510 30 0 0 0
								 4540 29 0 0 0
								 4540 25 0 0 0
								 4540 20 0 0 0
								 4540 15 0 0 0
								 4550 10 1 0 0>;
				strategy_temp_normal_high =	<4510 30 0 0 0
								 4540 29 0 0 0
								 4540 25 0 0 0
								 4540 20 0 0 0
								 4550 15 1 0 0>;
				strategy_temp_warm =		<4130 10 1 0 0>;
			};

			strategy_soc_85_to_90 { /* 86 ~ 90 */
				strategy_temp_little_cold =	<4510 10 1 0 0>;
				strategy_temp_cool =		<4510 10 1 0 0>;
				strategy_temp_little_cool =	<4540 15 0 0 0
								 4550 10 1 0 0>;
				strategy_temp_little_cool_high = <4540 20 0 0 0
								 4540 15 0 0 0
								 4550 10 1 0 0>;
				strategy_temp_normal_low =	<4540 20 0 0 0
								 4540 15 0 0 0
								 4550 10 1 0 0>;
				strategy_temp_normal_high =	<4540 25 0 0 0
								 4540 20 0 0 0
								 4550 15 1 0 0>;
				strategy_temp_warm =		<4130 10 1 0 0>;
			};
		};

		vooc_charge_strategy {
			strategy_soc_0_to_50 { /* 0 ~ 20 */
				strategy_temp_little_cold =	<4150 34 0 0 0
								 4150 30 0 0 0
								 4510 20 1 0 0>;
				strategy_temp_cool =		<4150 58 0 0 0
								 4150 50 0 0 0
								 4150 40 0 0 0
								 4500 34 0 0 0
								 4500 30 0 0 0
								 4510 20 1 0 0>;
				strategy_temp_little_cool =	<4150 60 0 0 0
								 4230 58 0 0 0
								 4230 50 0 0 0
								 4230 40 0 0 0
								 4540 34 0 0 0
								 4540 30 0 0 0
								 4550 20 1 0 0>;
				strategy_temp_little_cool_high =<4510 60 0 0 0
								 4540 58 0 0 0
								 4540 50 0 0 0
								 4540 40 0 0 0
								 4540 30 0 0 0
								 4550 20 1 0 0>;
				strategy_temp_normal_low =	<4510 60 0 0 0
								 4540 58 0 0 0
								 4540 50 0 0 0
								 4540 40 0 0 0
								 4540 30 0 0 0
								 4550 20 1 0 0>;
				strategy_temp_normal_high =	<4510 60 0 0 0
								 4540 58 0 0 0
								 4540 50 0 0 0
								 4540 40 0 0 0
								 4550 30 1 0 0>;
				strategy_temp_warm =		<4120 40 0 0 0
								 4120 30 0 0 0
								 4130 20 1 0 0>;
			};

			strategy_soc_0_to_50_mid { /* 21 ~ 35 */
				strategy_temp_little_cold =	<4150 34 0 0 0
								 4150 30 0 0 0
								 4510 20 1 0 0>;
				strategy_temp_cool =		<4150 58 0 0 0
								 4150 50 0 0 0
								 4150 40 0 0 0
								 4500 34 0 0 0
								 4500 30 0 0 0
								 4510 20 1 0 0>;
				strategy_temp_little_cool =	<4150 60 0 0 0
								 4230 58 0 0 0
								 4230 50 0 0 0
								 4230 40 0 0 0
								 4540 34 0 0 0
								 4540 30 0 0 0
								 4550 20 1 0 0>;
				strategy_temp_little_cool_high =<4510 60 0 0 0
								 4540 58 0 0 0
								 4540 50 0 0 0
								 4540 40 0 0 0
								 4540 30 0 0 0
								 4550 20 1 0 0>;
				strategy_temp_normal_low =	<4510 60 0 0 0
								 4540 58 0 0 0
								 4540 50 0 0 0
								 4540 40 0 0 0
								 4540 30 0 0 0
								 4550 20 1 0 0>;
				strategy_temp_normal_high =	<4510 60 0 0 0
								 4540 58 0 0 0
								 4540 50 0 0 0
								 4540 40 0 0 0
								 4550 30 1 0 0>;
				strategy_temp_warm =		<4120 40 0 0 0
								 4120 30 0 0 0
								 4130 20 1 0 0>;
			};

			strategy_soc_0_to_50_high { /* 36 ~ 55 */
				strategy_temp_little_cold =	<4150 34 0 0 0
								 4150 30 0 0 0
								 4510 20 1 0 0>;
				strategy_temp_cool =		<4150 50 0 0 0
								 4150 40 0 0 0
								 4500 34 0 0 0
								 4500 30 0 0 0
								 4510 20 1 0 0>;
				strategy_temp_little_cool =	<4150 60 0 0 0
								 4230 58 0 0 0
								 4230 50 0 0 0
								 4230 40 0 0 0
								 4540 34 0 0 0
								 4540 30 0 0 0
								 4550 20 1 0 0>;
				strategy_temp_little_cool_high =<4510 60 0 0 0
								 4540 58 0 0 0
								 4540 50 0 0 0
								 4540 40 0 0 0
								 4540 30 0 0 0
								 4550 20 1 0 0>;
				strategy_temp_normal_low =	<4510 60 0 0 0
								 4540 58 0 0 0
								 4540 50 0 0 0
								 4540 40 0 0 0
								 4540 30 0 0 0
								 4550 20 1 0 0>;
				strategy_temp_normal_high =	<4510 60 0 0 0
								 4540 58 0 0 0
								 4540 50 0 0 0
								 4540 40 0 0 0
								 4550 30 1 0 0>;
				strategy_temp_warm =		<4120 40 0 0 0
								 4120 30 0 0 0
								 4130 20 1 0 0>;
			};

			strategy_soc_50_to_75 { /* 56 ~ 75 */
				strategy_temp_little_cold =	<4150 30 0 0 0
								 4510 20 1 0 0>;
				strategy_temp_cool =		<4500 30 0 0 0
								 4510 20 1 0 0>;
				strategy_temp_little_cool =	<4230 50 0 0 0
								 4230 40 0 0 0
								 4540 34 0 0 0
								 4540 30 0 0 0
								 4550 20 1 0 0>;
				strategy_temp_little_cool_high =<4510 60 0 0 0
								 4540 58 0 0 0
								 4540 50 0 0 0
								 4540 40 0 0 0
								 4540 30 0 0 0
								 4550 20 1 0 0>;
				strategy_temp_normal_low =	<4510 60 0 0 0
								 4540 58 0 0 0
								 4540 50 0 0 0
								 4540 40 0 0 0
								 4540 30 0 0 0
								 4550 20 1 0 0>;
				strategy_temp_normal_high =	<4510 60 0 0 0
								 4540 58 0 0 0
								 4540 50 0 0 0
								 4540 40 0 0 0
								 4550 30 1 0 0>;
				strategy_temp_warm =		<4130 20 1 0 0>;
			};

			strategy_soc_75_to_85 { /* 76 ~ 85 */
				strategy_temp_little_cold =	<4510 20 1 0 0>;
				strategy_temp_cool =		<4500 30 0 0 0
								 4510 20 1 0 0>;
				strategy_temp_little_cool =	<4230 40 0 0 0
								 4540 34 0 0 0
								 4540 30 0 0 0
								 4550 20 1 0 0>;
				strategy_temp_little_cool_high =<4540 50 0 0 0
								 4540 40 0 0 0
								 4540 30 0 0 0
								 4550 20 1 0 0>;
				strategy_temp_normal_low =	<4510 60 0 0 0
								 4540 58 0 0 0
								 4540 50 0 0 0
								 4540 40 0 0 0
								 4540 30 0 0 0
								 4550 20 1 0 0>;
				strategy_temp_normal_high =	<4510 60 0 0 0
								 4540 58 0 0 0
								 4540 50 0 0 0
								 4540 40 0 0 0
								 4550 30 1 0 0>;
				strategy_temp_warm =		<4130 20 1 0 0>;
			};

			strategy_soc_85_to_90 { /* 86 ~ 90 */
				strategy_temp_little_cold =	<4510 20 1 0 0>;
				strategy_temp_cool =		<4510 20 1 0 0>;
				strategy_temp_little_cool =	<4540 30 0 0 0
								 4550 20 1 0 0>;
				strategy_temp_little_cool_high =<4540 40 0 0 0
								 4540 30 0 0 0
								 4550 20 1 0 0>;
				strategy_temp_normal_low =	<4540 40 0 0 0
								 4540 30 0 0 0
								 4550 20 1 0 0>;
				strategy_temp_normal_high =	<4540 50 0 0 0
								 4540 40 0 0 0
								 4550 30 1 0 0>;
				strategy_temp_warm =		<4120 42 0 0 0
								 4120 40 0 0 0
								 4120 30 0 0 0
								 4130 20 1 0 0>;
			};
		};

		oplus_sc8547_cp: oplus,sc8547_cp {
			oplus,ic_type = <OPLUS_CHG_IC_CP>;
			oplus,ic_index = <0>;
			oplus,ic_func_group = <&sc8547_cp_groups>;
		};
	};
};

&qupv3_se3_i2c {
	status = "okay";
	qcom,clk-freq-out = <400000>;

	oplus_sc8547_slave: sc8547-charger-slave@6A{
		status = "okay";
		compatible = "oplus,sc8547d";
		reg = <0x6A>;
		ocp_reg = <0xe>;
		ovp_reg = <0x36>;
		vbus_ovp_reg = /bits/ 8 <0x5A>;
		oplus,use_slave_cp;

		oplus_spec,irq_gpio = <&tlmm 28 0x00>;

		pinctrl-names = "charging_inter_active", "charging_inter_sleep";
		pinctrl-0 = <&slave_charging_inter_active>;
		pinctrl-1 = <&slave_charging_inter_sleep>;

		oplus_sc8547_slave_cp: oplus,sc8547_slave_cp {
			oplus,ic_type = <OPLUS_CHG_IC_CP>;
			oplus,ic_index = <1>;
		};
	};
};
//#endif OPLUS_FEATURE_CHG_BASIC /*for wired charging config*/


//#ifdef OPLUS_FEATURE_CHG_BASIC /*for ufcs config*/
&soc {
	oplus_virtual_cp: oplus,virtual_cp {
		compatible = "oplus,virtual_cp";

		oplus,ic_type = <OPLUS_CHG_IC_VIRTUAL_CP>;
		oplus,ic_index = <0>;

		oplus,cp_ic = <&oplus_sc8547_cp &oplus_sc8547_slave_cp>;
		oplus,input_curr_max_ma = <4000 4000>;

		oplus,cp_ic_connect = <OPLUS_CHG_IC_CONNECT_PARALLEL>;
		oplus,main_cp = <0>;

		oplus,reg_proc_node;

		oplus,cp_strategy = <CP_STRAT_OPEN_BY_CURR>;
		oplus,cp_strategy_data {
			oplus,cp_open_curr_thr_ma = <0 1900>;
			oplus,cp_close_curr_thr_ma = <0 1600>;
		};
	};

	oplus_virtual_ufcs: oplus,virtual_ufcs {
		compatible = "oplus,virtual_ufcs";

		oplus,ic_type = <OPLUS_CHG_IC_VIRTUAL_UFCS>;
		oplus,ic_index = <0>;
	};

	oplus_ufcs_charge: oplus,ufcs_charge {
		compatible = "oplus,ufcs_charge";
		oplus,ufcs_ic = <&oplus_virtual_ufcs>;
		oplus,cp_ic = <&oplus_virtual_cp>;
		oplus,dpdm_switch_ic = <&oplus_virtual_dpdm_switch>;
		oplus,impedance_unit = <&oplus_ufcs_impedance_unit>;

		oplus,target_vbus_mv = <11000>;
		oplus,curr_max_ma = <6100>;
		oplus,curr_max_ma_percent = <2000 /* 75% ibus */
					     1000 /* 85% ibus */>;
		oplus,curr_table_type = <UFCS_CURR_CP_TABLE>;
		oplus,high_imp_compensation_setting_mv = <250>;
		oplus,upper_compensation_mv = <200>;
		oplus,subboard_ntc_abnormal_current = <4000>;
		oplus,lift_vbus_use_cpvout;
		oplus,ufcs_need_reset_adapter;

		oplus,ufcs_warm_allow_vol = <4000>;
		oplus,ufcs_warm_allow_soc = <55>;
		oplus,ufcs_strategy_normal_current = <6100>;
		oplus,ufcs_over_high_or_low_current = <6100>;
		oplus,ufcs_timeout_third = <20108>;
		oplus,ufcs_timeout_oplus = <20108>;
		oplus,ufcs_ibat_over_third = <9400>;
		oplus,ufcs_ibat_over_oplus = <13600>;
		oplus,ufcs_ibus_over_oplus = <6800>;
		oplus,ufcs_full_cool_sw_vbat = <4550>;
		oplus,ufcs_full_normal_sw_vbat = <4550>;
		oplus,ufcs_full_normal_hw_vbat = <4560>;
		oplus,ufcs_full_warm_vbat = <4130>;
		oplus,ufcs_full_cool_sw_vbat_third = <4080>;
		oplus,ufcs_full_normal_sw_vbat_third= <4490>;
		oplus,ufcs_full_normal_hw_vbat_third = <4500>;
		oplus,ufcs_strategy_batt_high_temp = <405 420 430 395 410 425>;
		oplus,ufcs_strategy_high_current = <6000 5000 4000 4000 5000 6000>;
		oplus,ufcs_little_cool_high_temp = <210>;
		oplus,ufcs_full_recheck_temp = <210>;
		oplus,curve_strategy_name = "pps_ufcs_curve_v2";
		oplus_spec,ufcs_high_soc = <90>;
		oplus_spec,ufcs_high_soc_third = <85>;
		oplus_spec,ufcs_low_temp = <0>;
		oplus,ufcs_charge_strategy_temp = <0 50 120 160 350 440 510>;
		oplus,plc_strategy-data = <&oplus_ufcs_step_strategy &cp_2t1_simple_strategy>;
		oplus,plc_strategy-names = "default", "third";

 		oplus,temperature_strategy_name = "cgcl";
 		oplus,temperature_strategy_data = <OPLUS_STRATEGY_USE_SHELL_TEMP
 						0   415 10900 1 0
 						385 428 6000 2 0
 						415 440 5000 3 1
 						430 450 3500 4 2
 						440 460 2000 4 3>;

		ufcs_oplus_lcf_strategy {
			oplus,temp_type = <OPLUS_STRATEGY_USE_SHELL_TEMP>;
			oplus,temp_range = <0 50 120 160 210 380 440>;

			strategy_temp_range_curves {
				strategy_temp_range_t0 =	<400  4510 0
								 375  4500 0
								 350  4490 0
								 325  4480 0
								 300  4470 1>;
				strategy_temp_range_t1 =	<400  4510 0
								 365  4505 0
								 330  4490 0
								 295  4480 0
								 260  4470 1>;
				strategy_temp_range_t2 =	<1009 4550 0
								 959 4545 0
								 859 4530 0
								 759  4520 0
								 609  4510 1>;
				strategy_temp_range_t3 =	<1926 4550 0
								 1876 4545 0
								 1776 4530 0
								 1676 4520 0
								 1526 4510 1>;
				strategy_temp_range_t4 =	<1926 4550 0
								 1876 4545 0
								 1776 4530 0
								 1676 4520 0
								 1526 4510 1>;
				strategy_temp_range_t5 =	<2554 4546 0
								 2354 4543 0
								 1904 4505 0
								 1454 4488 0
								 1000 4471 1>;
			};
		};

		ufcs_third_lcf_strategy {
			oplus,temp_type = <OPLUS_STRATEGY_USE_SHELL_TEMP>;
			oplus,temp_range = <0 50 120 160 210 380 440>;

			strategy_temp_range_curves {
				strategy_temp_range_t0 =	<400  4510 0
								 375  4500 0
								 350  4490 0
								 325  4480 0
								 300  4470 1>;
				strategy_temp_range_t1 =	<400  4510 0
								 365  4505 0
								 330  4490 0
								 295  4480 0
								 260  4470 1>;
				strategy_temp_range_t2 =	<1009 4550 0
								 959 4545 0
								 859 4530 0
								 759  4520 0
								 609  4510 1>;
				strategy_temp_range_t3 =	<1926 4550 0
								 1876 4545 0
								 1776 4530 0
								 1676 4520 0
								 1526 4510 1>;
				strategy_temp_range_t4 =	<1926 4550 0
								 1876 4545 0
								 1776 4530 0
								 1676 4520 0
								 1526 4510 1>;
				strategy_temp_range_t5 =	<2554 4546 0
								 2354 4543 0
								 1904 4505 0
								 1454 4488 0
								 1000 4471 1>;
			};
		};

		ufcs_charge_third_strategy {
			oplus,temp_type = <OPLUS_STRATEGY_USE_SHELL_TEMP>;
			oplus,soc_range = <0 20 35 55 75 85 90>;
			oplus,temp_range = <0 50 120 160 210 350 440 510>;

			strategy_soc_range_min {
				strategy_temp_little_cold =	<11000 4140 1750 0 0
								11000 4140 1500 0 0
								11000 4150 1000 1 0>;
				strategy_temp_cool =	<11000 4150 2950 0 0
							11000 4150 2500 0 0
							11000 4150 2000 0 0
							11000 4480 1750 0 0
							11000 4480 1500 0 0
							11000 4490 1000 1 0>;
				strategy_temp_little_cool =	<11000 4150 3750 0 0
								11000 4150 3500 0 0
								11000 4150 3000 0 0
								11000 4230 2950 0 0
								11000 4230 2500 0 0
								11000 4230 2000 0 0
								11000 4480 1750 0 0
								11000 4480 1500 0 0
								11000 4490 1000 1 0>;
				strategy_temp_little_cool_high =	<11000 4480 4000 0 0
									11000 4480 3500 0 0
									11000 4480 3000 0 0
									11000 4480 2950 0 0
									11000 4480 2500 0 0
									11000 4480 2000 0 0
									11000 4480 1500 0 0
									11000 4490 1000 1 0>;
				strategy_temp_normal_low =	<11000 4480 4000 0 0
								11000 4480 3500 0 0
								11000 4480 3000 0 0
								11000 4480 2950 0 0
								11000 4480 2500 0 0
								11000 4480 2000 0 0
								11000 4480 1500 0 0
								11000 4490 1000 1 0>;
				strategy_temp_normal_high =	<11000 4460 4000 0 0
								11000 4460 3500 0 0
								11000 4460 3000 0 0
								11000 4460 2950 0 0
								11000 4460 2500 0 0
								11000 4460 2000 0 0
								11000 4460 1500 0 0
								11000 4470 1000 1 0>;
				strategy_temp_warm =	<11000 4120 2000 0 0
							11000 4120 1500 0 0
							11000 4130 1000 1 0>;
			};

			strategy_soc_range_low {
				strategy_temp_little_cold =	<11000 4140 1750 0 0
								11000 4140 1500 0 0
								11000 4150 1000 1 0>;
				strategy_temp_cool =	<11000 4150 2950 0 0
							11000 4150 2500 0 0
							11000 4150 2000 0 0
							11000 4480 1750 0 0
							11000 4480 1500 0 0
							11000 4490 1000 1 0>;
				strategy_temp_little_cool =	<11000 4150 3750 0 0
								11000 4150 3500 0 0
								11000 4150 3000 0 0
								11000 4230 2950 0 0
								11000 4230 2500 0 0
								11000 4230 2000 0 0
								11000 4480 1750 0 0
								11000 4480 1500 0 0
								11000 4490 1000 1 0>;
				strategy_temp_little_cool_high =	<11000 4480 4000 0 0
									11000 4480 3500 0 0
									11000 4480 3000 0 0
									11000 4480 2950 0 0
									11000 4480 2500 0 0
									11000 4480 2000 0 0
									11000 4480 1500 0 0
									11000 4490 1000 1 0>;
				strategy_temp_normal_low =	<11000 4480 4000 0 0
								11000 4480 3500 0 0
								11000 4480 3000 0 0
								11000 4480 2950 0 0
								11000 4480 2500 0 0
								11000 4480 2000 0 0
								11000 4480 1500 0 0
								11000 4490 1000 1 0>;
				strategy_temp_normal_high =	<11000 4460 4000 0 0
								11000 4460 3500 0 0
								11000 4460 3000 0 0
								11000 4460 2950 0 0
								11000 4460 2500 0 0
								11000 4460 2000 0 0
								11000 4460 1500 0 0
								11000 4470 1000 1 0>;
				strategy_temp_warm =	<11000 4120 2000 0 0
							11000 4120 1500 0 0
							11000 4130 1000 1 0>;
			};

			strategy_soc_range_mid_low {
				strategy_temp_little_cold =	<11000 4140 1750 0 0
								11000 4140 1500 0 0
								11000 4150 1000 1 0>;
				strategy_temp_cool =	<11000 4150 2500 0 0
							11000 4150 2000 0 0
							11000 4480 1750 0 0
							11000 4480 1500 0 0
							11000 4490 1000 1 0>;
				strategy_temp_little_cool =	<11000 4150 3750 0 0
								11000 4150 3500 0 0
								11000 4150 3000 0 0
								11000 4230 2950 0 0
								11000 4230 2500 0 0
								11000 4230 2000 0 0
								11000 4480 1750 0 0
								11000 4480 1500 0 0
								11000 4490 1000 1 0>;
				strategy_temp_little_cool_high =	<11000 4480 4000 0 0
									11000 4480 3500 0 0
									11000 4480 3000 0 0
									11000 4480 2950 0 0
									11000 4480 2500 0 0
									11000 4480 2000 0 0
									11000 4480 1500 0 0
									11000 4490 1000 1 0>;
				strategy_temp_normal_low =	<11000 4480 4000 0 0
								11000 4480 3500 0 0
								11000 4480 3000 0 0
								11000 4480 2950 0 0
								11000 4480 2500 0 0
								11000 4480 2000 0 0
								11000 4480 1500 0 0
								11000 4490 1000 1 0>;
				strategy_temp_normal_high =	<11000 4460 4000 0 0
								11000 4460 3500 0 0
								11000 4460 3000 0 0
								11000 4460 2950 0 0
								11000 4460 2500 0 0
								11000 4460 2000 0 0
								11000 4460 1500 0 0
								11000 4470 1000 1 0>;
				strategy_temp_warm =	<11000 4120 2000 0 0
							11000 4120 1500 0 0
							11000 4130 1000 1 0>;
			};

			strategy_soc_range_mid {
				strategy_temp_little_cold =	<11000 4140 1500 0 0
								11000 4150 1000 1 0>;
				strategy_temp_cool =	<11000 4480 1500 0 0
							11000 4490 1000 1 0>;
				strategy_temp_little_cool =	<11000 4230 2500 0 0
								11000 4230 2000 0 0
								11000 4480 1750 0 0
								11000 4480 1500 0 0
								11000 4490 1000 1 0>;
				strategy_temp_little_cool_high =	<11000 4480 3000 0 0
									11000 4480 2950 0 0
									11000 4480 2500 0 0
									11000 4480 2000 0 0
									11000 4480 1500 0 0
									11000 4490 1000 1 0>;
				strategy_temp_normal_low =	<11000 4480 3000 0 0
								11000 4480 2950 0 0
								11000 4480 2500 0 0
								11000 4480 2000 0 0
								11000 4480 1500 0 0
								11000 4490 1000 1 0>;
				strategy_temp_normal_high =	<11000 4460 3500 0 0
								11000 4460 3000 0 0
								11000 4460 2950 0 0
								11000 4460 2500 0 0
								11000 4460 2000 0 0
								11000 4460 1500 0 0
								11000 4470 1000 1 0>;
				strategy_temp_warm =	<11000 4130 1100 1 0>;
			};

			strategy_soc_range_mid_high {
				strategy_temp_little_cold =	<11000 4150 1000 1 0>;
				strategy_temp_cool =	<11000 4480 1500 0 0
							11000 4490 1000 1 0>;
				strategy_temp_little_cool =	<11000 4230 2000 0 0
								11000 4480 1750 0 0
								11000 4480 1500 0 0
								11000 4490 1000 1 0>;
				strategy_temp_little_cool_high =	<11000 4480 2500 0 0
									11000 4480 2000 0 0
									11000 4480 1500 0 0
									11000 4490 1000 1 0>;
				strategy_temp_normal_low =	<11000 4480 3000 0 0
								11000 4480 2950 0 0
								11000 4480 2500 0 0
								11000 4480 2000 0 0
								11000 4480 1500 0 0
								11000 4490 1000 1 0>;
				strategy_temp_normal_high =	<11000 4460 3000 0 0
								11000 4460 2950 0 0
								11000 4460 2500 0 0
								11000 4460 2000 0 0
								11000 4460 1500 0 0
								11000 4470 1000 1 0>;
				strategy_temp_warm =	<11000 4130 1100 1 0>;
			};

			strategy_soc_range_high {
				strategy_temp_little_cold =	<11000 4150 1000 1 0>;
				strategy_temp_cool =	<11000 4490 1000 1 0>;
				strategy_temp_little_cool =	<11000 4480 1500 0 0
								11000 4490 1000 1 0>;
				strategy_temp_little_cool_high =	<11000 4480 2000 0 0
									11000 4480 1500 0 0
									11000 4490 1000 1 0>;
				strategy_temp_normal_low =	<11000 4480 2000 0 0
								11000 4480 1500 0 0
								11000 4490 1000 1 0>;
				strategy_temp_normal_high =	<11000 4460 2500 0 0
								11000 4460 2000 0 0
								11000 4460 1500 0 0
								11000 4470 1000 1 0>;
				strategy_temp_warm =	<11000 4130 1100 1 0>;
			};

		};

		ufcs_charge_oplus_strategy {
			oplus,temp_type = <OPLUS_STRATEGY_USE_SHELL_TEMP>;
			oplus,soc_range = <0 20 35 55 75 85 90>;
			oplus,temp_range = <0 50 120 160 210 350 440 510>;

			strategy_soc_range_min {
				strategy_temp_little_cold =	<11000 4150 1750 0 0
								11000 4150 1500 0 0
								11000 4510 1000 1 0>;
				strategy_temp_cool =		<11000 4150 2950 0 0
								11000 4150 2500 0 0
								11000 4150 2000 0 0
								11000 4500 1750 0 0
								11000 4500 1500 0 0
								11000 4510 1000 1 0>;
				strategy_temp_little_cool =	<11000 4150 3750 0 0
								11000 4150 3500 0 0
								11000 4150 3000 0 0
								11000 4230 2950 0 0
								11000 4230 2500 0 0
								11000 4230 2000 0 0
								11000 4540 1750 0 0
								11000 4540 1500 0 0
								11000 4550 1000 1 0>;
				strategy_temp_little_cool_high = <11000 4150 6100 0 0
								11000 4150 6000 0 0
								11000 4230 5600 0 0
								11000 4230 5500 0 0
								11000 4230 5000 0 0
								11000 4510 4500 0 0
								11000 4510 4000 0 0
								11000 4510 3500 0 0
								11000 4510 3000 0 0
								11000 4540 2950 0 0
								11000 4540 2500 0 0
								11000 4540 2000 0 0
								11000 4540 1500 0 0
								11000 4550 1000 1 0>;
				strategy_temp_normal_low =	<11000 4150 6100 0 30
								11000 4150 6000 0 30
								11000 4230 5600 0 60
								11000 4230 5500 0 120
								11000 4230 5000 0 0
								11000 4510 4500 0 0
								11000 4510 4000 0 0
								11000 4510 3500 0 0
								11000 4510 3000 0 0
								11000 4540 2950 0 0
								11000 4540 2500 0 0
								11000 4540 2000 0 0
								11000 4540 1500 0 0
								11000 4550 1000 1 0>;
				strategy_temp_normal_high =	<11000 4150 6100 0 30
								11000 4150 6000 0 30
								11000 4230 5600 0 60
								11000 4230 5500 0 120
								11000 4230 5000 0 0
								11000 4510 4500 0 0
								11000 4510 4000 0 0
								11000 4510 3500 0 0
								11000 4510 3000 0 0
								11000 4540 2950 0 0
								11000 4540 2500 0 0
								11000 4540 2000 0 0
								11000 4540 1500 0 0
								11000 4550 1450 1 0>;
				strategy_temp_warm =		<11000 4120 2000 0 0
								11000 4120 1500 0 0
								11000 4130 1000 1 0>;
			};
			strategy_soc_range_low {
				strategy_temp_little_cold =	<11000 4150 1750 0 0
								11000 4150 1500 0 0
								11000 4510 1000 1 0>;
				strategy_temp_cool =		<11000 4150 2950 0 0
								11000 4150 2500 0 0
								11000 4150 2000 0 0
								11000 4500 1750 0 0
								11000 4500 1500 0 0
								11000 4510 1000 1 0>;
				strategy_temp_little_cool =	<11000 4150 3750 0 0
								11000 4150 3500 0 0
								11000 4150 3000 0 0
								11000 4230 2950 0 0
								11000 4230 2500 0 0
								11000 4230 2000 0 0
								11000 4540 1750 0 0
								11000 4540 1500 0 0
								11000 4550 1000 1 0>;
				strategy_temp_little_cool_high = <11000 4150 6100 0 0
								11000 4150 6000 0 0
								11000 4230 5600 0 0
								11000 4230 5500 0 0
								11000 4230 5000 0 0
								11000 4510 4500 0 0
								11000 4510 4000 0 0
								11000 4510 3500 0 0
								11000 4510 3000 0 0
								11000 4540 2950 0 0
								11000 4540 2500 0 0
								11000 4540 2000 0 0
								11000 4540 1500 0 0
								11000 4550 1000 1 0>;
				strategy_temp_normal_low =	<11000 4150 6100 0 30
								11000 4150 6000 0 30
								11000 4230 5600 0 60
								11000 4230 5500 0 120
								11000 4230 5000 0 0
								11000 4510 4500 0 0
								11000 4510 4000 0 0
								11000 4510 3500 0 0
								11000 4510 3000 0 0
								11000 4540 2950 0 0
								11000 4540 2500 0 0
								11000 4540 2000 0 0
								11000 4540 1500 0 0
								11000 4550 1000 1 0>;
				strategy_temp_normal_high =	<11000 4150 6100 0 30
								11000 4150 6000 0 30
								11000 4230 5600 0 60
								11000 4230 5500 0 120
								11000 4230 5000 0 0
								11000 4510 4500 0 0
								11000 4510 4000 0 0
								11000 4510 3500 0 0
								11000 4510 3000 0 0
								11000 4540 2950 0 0
								11000 4540 2500 0 0
								11000 4540 2000 0 0
								11000 4540 1500 0 0
								11000 4550 1450 1 0>;
				strategy_temp_warm =		<11000 4120 2000 0 0
								11000 4120 1500 0 0
								11000 4130 1000 1 0>;
			};
			strategy_soc_range_mid_low {
				strategy_temp_little_cold =	<11000 4150 1750 0 0
								11000 4150 1500 0 0
								11000 4510 1000 1 0>;
				strategy_temp_cool =		<11000 4150 2500 0 0
								11000 4150 2000 0 0
								11000 4500 1750 0 0
								11000 4500 1500 0 0
								11000 4510 1000 1 0>;
				strategy_temp_little_cool =	<11000 4150 3750 0 0
								11000 4150 3500 0 0
								11000 4150 3000 0 0
								11000 4230 2950 0 0
								11000 4230 2500 0 0
								11000 4230 2000 0 0
								11000 4540 1750 0 0
								11000 4540 1500 0 0
								11000 4550 1000 1 0>;
				strategy_temp_little_cool_high = <11000 4510 4000 0 0
								11000 4510 3500 0 0
								11000 4510 3000 0 0
								11000 4540 2950 0 0
								11000 4540 2500 0 0
								11000 4540 2000 0 0
								11000 4540 1500 0 0
								11000 4550 1000 1 0>;
				strategy_temp_normal_low =	<11000 4150 6100 0 30
								11000 4150 6000 0 30
								11000 4230 5600 0 60
								11000 4230 5500 0 120
								11000 4230 5000 0 0
								11000 4510 4500 0 0
								11000 4510 4000 0 0
								11000 4510 3500 0 0
								11000 4510 3000 0 0
								11000 4540 2950 0 0
								11000 4540 2500 0 0
								11000 4540 2000 0 0
								11000 4540 1500 0 0
								11000 4550 1000 1 0>;
				strategy_temp_normal_high =	<11000 4150 6100 0 30
								11000 4150 6000 0 30
								11000 4230 5600 0 60
								11000 4230 5500 0 120
								11000 4230 5000 0 0
								11000 4510 4500 0 0
								11000 4510 4000 0 0
								11000 4510 3500 0 0
								11000 4510 3000 0 0
								11000 4540 2950 0 0
								11000 4540 2500 0 0
								11000 4540 2000 0 0
								11000 4540 1500 0 0
								11000 4550 1450 1 0>;
				strategy_temp_warm =		<11000 4120 2000 0 0
								11000 4120 1500 0 0
								11000 4130 1000 1 0>;
			};
			strategy_soc_range_mid {
				strategy_temp_little_cold =	<11000 4150 1500 0 0
								11000 4510 1000 1 0>;
				strategy_temp_cool =		<11000 4500 1500 0 0
								11000 4510 1000 1 0>;
				strategy_temp_little_cool =	<11000 4230 2500 0 0
								11000 4230 2000 0 0
								11000 4540 1750 0 0
								11000 4540 1500 0 0
								11000 4550 1000 1 0>;
				strategy_temp_little_cool_high = <11000 4510 3000 0 0
								11000 4540 2950 0 0
								11000 4540 2500 0 0
								11000 4540 2000 0 0
								11000 4540 1500 0 0
								11000 4550 1000 1 0>;
				strategy_temp_normal_low =	<11000 4510 3000 0 0
								11000 4540 2950 0 0
								11000 4540 2500 0 0
								11000 4540 2000 0 0
								11000 4540 1500 0 0
								11000 4550 1000 1 0>;
				strategy_temp_normal_high =	<11000 4510 3500 0 0
								11000 4510 3000 0 0
								11000 4540 2950 0 0
								11000 4540 2500 0 0
								11000 4540 2000 0 0
								11000 4540 1500 0 0
								11000 4550 1450 1 0>;
				strategy_temp_warm =		<11000 4130 1000 1 0>;
			};
			strategy_soc_range_mid_high {
				strategy_temp_little_cold =	<11000 4510 1000 1 0>;
				strategy_temp_cool =		<11000 4500 1500 0 0
								11000 4510 1000 1 0>;
				strategy_temp_little_cool =	<11000 4230 2000 0 0
								11000 4540 1750 0 0
								11000 4540 1500 0 0
								11000 4550 1000 1 0>;
				strategy_temp_little_cool_high = <11000 4540 2500 0 0
								11000 4540 2000 0 0
								11000 4540 1500 0 0
								11000 4550 1000 1 0>;
				strategy_temp_normal_low =	<11000 4510 3000 0 0
								11000 4540 2950 0 0
								11000 4540 2500 0 0
								11000 4540 2000 0 0
								11000 4540 1500 0 0
								11000 4550 1000 1 0>;
				strategy_temp_normal_high =	<11000 4510 3000 0 0
								11000 4540 2950 0 0
								11000 4540 2500 0 0
								11000 4540 2000 0 0
								11000 4540 1500 0 0
								11000 4550 1450 1 0>;
				strategy_temp_warm =		<11000 4130 500 1 0>;
			};
			strategy_soc_range_high {
				strategy_temp_little_cold =	<11000 4510 1000 1 0>;
				strategy_temp_cool =		<11000 4510 1000 1 0>;
				strategy_temp_little_cool =	<11000 4540 1500 0 0
								11000 4550 1000 1 0>;
				strategy_temp_little_cool_high = <11000 4540 2000 0 0
								11000 4540 1500 0 0
								11000 4550 1000 1 0>;
				strategy_temp_normal_low =	<11000 4540 2000 0 0
								11000 4540 1500 0 0
								11000 4550 1000 1 0>;
				strategy_temp_normal_high =	<11000 4540 2500 0 0
								11000 4540 2000 0 0
								11000 4540 1500 0 0
								11000 4550 1450 1 0>;
				strategy_temp_warm =		<11000 4130 500 1 0>;
			};
		};

		oplus,impedance_node {
			ufcs_input_impedance: ufcs_input_impedance {
				node_name = "ufcs_input";
				default_impedance_mohm = <0>;
				default_curr_ma = <6100>;
				current_drop_table = <
					125 10000
					130 8000
					190 5000
					250 4000
					340 3000
					380 2000
					480 0
				>;
			};
		};
	};
	oplus_ufcs_impedance_check: oplus,ufcs_impedance_check {
		compatible = "oplus,impedance_check";

		oplus,impedance_unit {
			oplus_ufcs_impedance_unit: oplus,ufcs_impedance_unit {
				uint_name = "ufcs";
				default_curr_ma = <6100>;
				impedance_node = <&ufcs_input_impedance>;
			};
		};
	};
};
//#endif OPLUS_FEATURE_CHG_BASIC /*for ufcs config*/

//#ifdef OPLUS_FEATURE_CHG_BASIC /*for pps config*/
&soc {
	oplus_virtual_pps: oplus,virtual_pps {
		compatible = "oplus,virtual_pps";

		oplus,ic_type = <OPLUS_CHG_IC_VIRTUAL_PPS>;
		oplus,ic_index = <0>;
		oplus,pps_ic = <&oplus_adsp_pps>;
	};
	oplus_pps_charge: oplus,pps_charge {
		compatible = "oplus,pps_charge";
		oplus,pps_ic = <&oplus_virtual_pps>;
		oplus,cp_ic = <&oplus_virtual_cp>;
		oplus,dpdm_switch_ic = <&oplus_virtual_dpdm_switch>;

		oplus,target_vbus_mv = <11000>;
		oplus,curr_max_ma = <5000>;
		oplus,curr_max_ma_percent = <2500 /* 75% ibus */
					     1000 /* 85% ibus */>;

		oplus,lift_vbus_use_cpvout;
		oplus,process_close_cp_item;

		oplus,pps_warm_allow_vol = <4000>;
		oplus,pps_warm_allow_soc = <55>;
		oplus,pps_strategy_normal_current = <5000>;
		oplus,pps_over_high_or_low_current = <5000>;
		oplus,pps_timeout_third = <20108>;
		oplus,pps_timeout_oplus = <20108>;
		oplus,pps_ibat_over_third = <11400>;
		oplus,pps_ibat_over_oplus = <11400>;
		oplus,pps_full_cool_sw_vbat = <4490>;
		oplus,pps_full_normal_sw_vbat = <4490>;
		oplus,pps_full_normal_hw_vbat = <4500>;
		oplus,pps_full_warm_vbat = <4130>;
		oplus,pps_full_cool_sw_vbat_third = <4490>;
		oplus,pps_full_normal_sw_vbat_third= <4490>;
		oplus,pps_full_normal_hw_vbat_third = <4500>;
		oplus,pps_current_change_timeout = <100>;
		oplus,pps_strategy_batt_high_temp = <410 420 430 400 410 420>;
		oplus,pps_strategy_high_current = <5000 4000 3000 5000 5000 4000>;
		oplus,pps_little_cool_high_temp = <210>;
		oplus,pps_full_recheck_temp = <210>;
		oplus,pps_low_temp = <0>;
		oplus,curve_strategy_name = "pps_ufcs_curve_v2";
		oplus,pps_charge_strategy_soc = <0 20 35 55 75 85 85>;
		oplus,pps_charge_strategy_temp = <0 50 120 160 350 440 510>;
		oplus,plc_strategy-data = <&cp_2t1_simple_strategy>;
		oplus,plc_strategy-names = "default";
 		oplus,temperature_strategy_name = "cgcl";
 		oplus,temperature_strategy_data = <OPLUS_STRATEGY_USE_SHELL_TEMP
 						0   385 7300 1 0
 						375 405 5000 2 0
 						395 420 4000 3 1
 						410 430 3500 4 2
 						420 440 2000 4 3>;

		pps_oplus_lcf_strategy {
			oplus,temp_type = <OPLUS_STRATEGY_USE_SHELL_TEMP>;
			oplus,temp_range = <0 50 120 160 210 380 440>;

			strategy_temp_range_curves {
				strategy_temp_range_t0 =	<400  4510 0
								 375  4500 0
								 350  4490 0
								 325  4480 0
								 300  4470 1>;
				strategy_temp_range_t1 =	<400  4510 0
								 365  4505 0
								 330  4490 0
								 295  4480 0
								 260  4470 1>;
				strategy_temp_range_t2 =	<1009 4550 0
								 959 4545 0
								 859 4530 0
								 759  4520 0
								 609  4510 1>;
				strategy_temp_range_t3 =	<1926 4550 0
								 1876 4545 0
								 1776 4530 0
								 1676 4520 0
								 1526 4510 1>;
				strategy_temp_range_t4 =	<1926 4550 0
								 1876 4545 0
								 1776 4530 0
								 1676 4520 0
								 1526 4510 1>;
				strategy_temp_range_t5 =	<2554 4546 0
								 2354 4543 0
								 1904 4505 0
								 1454 4488 0
								 1000 4471 1>;
			};
		};

		pps_third_lcf_strategy {
			oplus,temp_type = <OPLUS_STRATEGY_USE_SHELL_TEMP>;
			oplus,temp_range = <0 50 120 160 210 380 440>;

			strategy_temp_range_curves {
				strategy_temp_range_t0 =	<400  4510 0
								 375  4500 0
								 350  4490 0
								 325  4480 0
								 300  4470 1>;
				strategy_temp_range_t1 =	<400  4510 0
								 365  4505 0
								 330  4490 0
								 295  4480 0
								 260  4470 1>;
				strategy_temp_range_t2 =	<1009 4550 0
								 959 4545 0
								 859 4530 0
								 759  4520 0
								 609  4510 1>;
				strategy_temp_range_t3 =	<1926 4550 0
								 1876 4545 0
								 1776 4530 0
								 1676 4520 0
								 1526 4510 1>;
				strategy_temp_range_t4 =	<1926 4550 0
								 1876 4545 0
								 1776 4530 0
								 1676 4520 0
								 1526 4510 1>;
				strategy_temp_range_t5 =	<2554 4546 0
								 2354 4543 0
								 1904 4505 0
								 1454 4488 0
								 1000 4471 1>;
			};
		};

		pps_charge_third_strategy {
			oplus,temp_type = <OPLUS_STRATEGY_USE_SHELL_TEMP>;
			oplus,soc_range = <0 20 35 55 75 85 90>;
			oplus,temp_range = <0 50 120 160 210 350 440 510>;

			strategy_soc_range_min {
				strategy_temp_little_cold =	<11000 4140 1750 0 0
								11000 4140 1500 0 0
								11000 4150 1000 1 0>;
				strategy_temp_cool =		<11000 4150 2950 0 0
								11000 4150 2500 0 0
								11000 4150 2000 0 0
								11000 4480 1750 0 0
								11000 4480 1500 0 0
								11000 4490 1000 1 0>;
				strategy_temp_little_cool =	<11000 4150 3750 0 0
								11000 4150 3500 0 0
								11000 4150 3000 0 0
								11000 4230 2950 0 0
								11000 4230 2500 0 0
								11000 4230 2000 0 0
								11000 4480 1750 0 0
								11000 4480 1500 0 0
								11000 4490 1000 1 0>;
				strategy_temp_little_cool_high = <11000 4230 5000 0 0
								11000 4480 4500 0 0
								11000 4480 4000 0 0
								11000 4480 3500 0 0
								11000 4480 3000 0 0
								11000 4480 2950 0 0
								11000 4480 2500 0 0
								11000 4480 2000 0 0
								11000 4480 1500 0 0
								11000 4490 1000 1 0>;
				strategy_temp_normal_low =	<11000 4230 5000 0 0
								11000 4480 4500 0 0
								11000 4480 4000 0 0
								11000 4480 3500 0 0
								11000 4480 3000 0 0
								11000 4480 2950 0 0
								11000 4480 2500 0 0
								11000 4480 2000 0 0
								11000 4480 1500 0 0
								11000 4490 1000 1 0>;
				strategy_temp_normal_high =	<11000 4230 5000 0 0
								11000 4460 4500 0 0
								11000 4460 4000 0 0
								11000 4460 3500 0 0
								11000 4460 3000 0 0
								11000 4460 2950 0 0
								11000 4460 2500 0 0
								11000 4460 2000 0 0
								11000 4460 1500 0 0
								11000 4470 1000 1 0>;
				strategy_temp_warm =		<11000 4120 2000 0 0
								11000 4120 1500 0 0
								11000 4130 1000 1 0>;
			};
			strategy_soc_range_low {
				strategy_temp_little_cold =	<11000 4140 1750 0 0
								11000 4140 1500 0 0
								11000 4150 1000 1 0>;
				strategy_temp_cool =		<11000 4150 2950 0 0
								11000 4150 2500 0 0
								11000 4150 2000 0 0
								11000 4480 1750 0 0
								11000 4480 1500 0 0
								11000 4490 1000 1 0>;
				strategy_temp_little_cool =	<11000 4150 3750 0 0
								11000 4150 3500 0 0
								11000 4150 3000 0 0
								11000 4230 2950 0 0
								11000 4230 2500 0 0
								11000 4230 2000 0 0
								11000 4480 1750 0 0
								11000 4480 1500 0 0
								11000 4490 1000 1 0>;
				strategy_temp_little_cool_high = <11000 4230 5000 0 0
								11000 4480 4500 0 0
								11000 4480 4000 0 0
								11000 4480 3500 0 0
								11000 4480 3000 0 0
								11000 4480 2950 0 0
								11000 4480 2500 0 0
								11000 4480 2000 0 0
								11000 4480 1500 0 0
								11000 4490 1000 1 0>;
				strategy_temp_normal_low =	<11000 4230 5000 0 0
								11000 4480 4500 0 0
								11000 4480 4000 0 0
								11000 4480 3500 0 0
								11000 4480 3000 0 0
								11000 4480 2950 0 0
								11000 4480 2500 0 0
								11000 4480 2000 0 0
								11000 4480 1500 0 0
								11000 4490 1000 1 0>;
				strategy_temp_normal_high =	<11000 4230 5000 0 0
								11000 4460 4500 0 0
								11000 4460 4000 0 0
								11000 4460 3500 0 0
								11000 4460 3000 0 0
								11000 4460 2950 0 0
								11000 4460 2500 0 0
								11000 4460 2000 0 0
								11000 4460 1500 0 0
								11000 4470 1000 1 0>;
				strategy_temp_warm =		<11000 4120 2000 0 0
								11000 4120 1500 0 0
								11000 4130 1000 1 0>;
			};
			strategy_soc_range_mid_low {
				strategy_temp_little_cold =	<11000 4140 1750 0 0
								11000 4140 1500 0 0
								11000 4150 1000 1 0>;
				strategy_temp_cool =		<11000 4150 2500 0 0
								11000 4150 2000 0 0
								11000 4480 1750 0 0
								11000 4480 1500 0 0
								11000 4490 1000 1 0>;
				strategy_temp_little_cool =	<11000 4150 3750 0 0
								11000 4150 3500 0 0
								11000 4150 3000 0 0
								11000 4230 2950 0 0
								11000 4230 2500 0 0
								11000 4230 2000 0 0
								11000 4480 1750 0 0
								11000 4480 1500 0 0
								11000 4490 1000 1 0>;
				strategy_temp_little_cool_high = <11000 4480 4000 0 0
								11000 4480 3500 0 0
								11000 4480 3000 0 0
								11000 4480 2950 0 0
								11000 4480 2500 0 0
								11000 4480 2000 0 0
								11000 4480 1500 0 0
								11000 4490 1000 1 0>;
				strategy_temp_normal_low =	<11000 4230 5000 0 0
								11000 4480 4500 0 0
								11000 4480 4000 0 0
								11000 4480 3500 0 0
								11000 4480 3000 0 0
								11000 4480 2950 0 0
								11000 4480 2500 0 0
								11000 4480 2000 0 0
								11000 4480 1500 0 0
								11000 4490 1000 1 0>;
				strategy_temp_normal_high =	<11000 4230 5000 0 0
								11000 4460 4500 0 0
								11000 4460 4000 0 0
								11000 4460 3500 0 0
								11000 4460 3000 0 0
								11000 4460 2950 0 0
								11000 4460 2500 0 0
								11000 4460 2000 0 0
								11000 4460 1500 0 0
								11000 4470 1000 1 0>;
				strategy_temp_warm =		<11000 4120 2000 0 0
								11000 4120 1500 0 0
								11000 4130 1000 1 0>;
			};
			strategy_soc_range_mid {
				strategy_temp_little_cold =	<11000 4140 1500 0 0
								11000 4150 1000 1 0>;
				strategy_temp_cool =		<11000 4480 1500 0 0
								11000 4490 1000 1 0>;
				strategy_temp_little_cool =	<11000 4230 2500 0 0
								11000 4230 2000 0 0
								11000 4480 1750 0 0
								11000 4480 1500 0 0
								11000 4490 1000 1 0>;
				strategy_temp_little_cool_high = <11000 4480 3000 0 0
								11000 4480 2950 0 0
								11000 4480 2500 0 0
								11000 4480 2000 0 0
								11000 4480 1500 0 0
								11000 4490 1000 1 0>;
				strategy_temp_normal_low =	<11000 4480 3000 0 0
								11000 4480 2950 0 0
								11000 4480 2500 0 0
								11000 4480 2000 0 0
								11000 4480 1500 0 0
								11000 4490 1000 1 0>;
				strategy_temp_normal_high =	<11000 4460 3500 0 0
								11000 4460 3000 0 0
								11000 4460 2950 0 0
								11000 4460 2500 0 0
								11000 4460 2000 0 0
								11000 4460 1500 0 0
								11000 4470 1000 1 0>;
				strategy_temp_warm =		<11000 4130 1000 1 0>;
			};
			strategy_soc_range_mid_high {
				strategy_temp_little_cold =	<11000 4150 1000 1 0>;
				strategy_temp_cool =		<11000 4480 1500 0 0
								11000 4490 1000 1 0>;
				strategy_temp_little_cool =	<11000 4230 2000 0 0
								11000 4480 1750 0 0
								11000 4480 1500 0 0
								11000 4490 1000 1 0>;
				strategy_temp_little_cool_high = <11000 4480 2500 0 0
								11000 4480 2000 0 0
								11000 4480 1500 0 0
								11000 4490 1000 1 0>;
				strategy_temp_normal_low =	<11000 4480 3000 0 0
								11000 4480 2950 0 0
								11000 4480 2500 0 0
								11000 4480 2000 0 0
								11000 4480 1500 0 0
								11000 4490 1000 1 0>;
				strategy_temp_normal_high =	<11000 4460 3000 0 0
								11000 4460 2950 0 0
								11000 4460 2500 0 0
								11000 4460 2000 0 0
								11000 4460 1500 0 0
								11000 4470 1000 1 0>;
				strategy_temp_warm =		<11000 4130 1000 1 0>;
			};
			strategy_soc_range_high {
				strategy_temp_little_cold =	<11000 4150 1000 1 0>;
				strategy_temp_cool =		<11000 4490 1000 1 0>;
				strategy_temp_little_cool =	<11000 4480 1500 0 0
								11000 4490 1000 1 0>;
				strategy_temp_little_cool_high = <11000 4480 2000 0 0
								11000 4480 1500 0 0
								11000 4490 1000 1 0>;
				strategy_temp_normal_low =	<11000 4480 2000 0 0
								11000 4480 1500 0 0
								11000 4490 1000 1 0>;
				strategy_temp_normal_high =	<11000 4460 2500 0 0
								11000 4460 2000 0 0
								11000 4460 1500 0 0
								11000 4470 1000 1 0>;
				strategy_temp_warm =		<11000 4130 1000 1 0>;
			};
		};

		pps_charge_oplus_strategy {
			oplus,temp_type = <OPLUS_STRATEGY_USE_SHELL_TEMP>;
			oplus,soc_range = <0 20 35 55 75 85 90>;
			oplus,temp_range = <0 50 120 160 210 350 440 510>;

			strategy_soc_range_min {
				strategy_temp_little_cold =	<11000 4140 1750 0 0
								11000 4140 1500 0 0
								11000 4150 1000 1 0>;
				strategy_temp_cool =		<11000 4150 2950 0 0
								11000 4150 2500 0 0
								11000 4150 2000 0 0
								11000 4480 1750 0 0
								11000 4480 1500 0 0
								11000 4490 1000 1 0>;
				strategy_temp_little_cool =	<11000 4150 3750 0 0
								11000 4150 3500 0 0
								11000 4230 2950 0 0
								11000 4230 2500 0 0
								11000 4230 2000 0 0
								11000 4480 1750 0 0
								11000 4480 1500 0 0
								11000 4490 1000 1 0>;
				strategy_temp_little_cool_high = <11000 4230 5000 0 0
								11000 4480 4500 0 0
								11000 4480 4000 0 0
								11000 4480 3500 0 0
								11000 4480 3000 0 0
								11000 4480 2950 0 0
								11000 4480 2500 0 0
								11000 4480 2000 0 0
								11000 4480 1500 0 0
								11000 4490 1000 1 0>;
				strategy_temp_normal_low =	<11000 4230 5000 0 0
								11000 4480 4500 0 0
								11000 4480 4000 0 0
								11000 4480 3500 0 0
								11000 4480 3000 0 0
								11000 4480 2950 0 0
								11000 4480 2500 0 0
								11000 4480 2000 0 0
								11000 4480 1500 0 0
								11000 4490 1000 1 0>;
				strategy_temp_normal_high =	<11000 4230 5000 0 0
								11000 4460 4500 0 0
								11000 4460 4000 0 0
								11000 4460 3500 0 0
								11000 4460 3000 0 0
								11000 4460 2950 0 0
								11000 4460 2500 0 0
								11000 4460 2000 0 0
								11000 4460 1500 0 0
								11000 4470 1000 1 0>;
				strategy_temp_warm =		<11000 4120 2000 0 0
								11000 4120 1500 0 0
								11000 4130 1000 1 0>;
			};
			strategy_soc_range_low {
				strategy_temp_little_cold =	<11000 4140 1750 0 0
								11000 4140 1500 0 0
								11000 4150 1000 1 0>;
				strategy_temp_cool =		<11000 4150 2950 0 0
								11000 4150 2500 0 0
								11000 4150 2000 0 0
								11000 4480 1750 0 0
								11000 4480 1500 0 0
								11000 4490 1000 1 0>;
				strategy_temp_little_cool =	<11000 4150 3750 0 0
								11000 4150 3500 0 0
								11000 4230 2950 0 0
								11000 4230 2500 0 0
								11000 4230 2000 0 0
								11000 4480 1750 0 0
								11000 4480 1500 0 0
								11000 4490 1000 1 0>;
				strategy_temp_little_cool_high = <11000 4230 5000 0 0
								11000 4480 4500 0 0
								11000 4480 4000 0 0
								11000 4480 3500 0 0
								11000 4480 3000 0 0
								11000 4480 2950 0 0
								11000 4480 2500 0 0
								11000 4480 2000 0 0
								11000 4480 1500 0 0
								11000 4490 1000 1 0>;
				strategy_temp_normal_low =	<11000 4230 5000 0 0
								11000 4480 4500 0 0
								11000 4480 4000 0 0
								11000 4480 3500 0 0
								11000 4480 3000 0 0
								11000 4480 2950 0 0
								11000 4480 2500 0 0
								11000 4480 2000 0 0
								11000 4480 1500 0 0
								11000 4490 1000 1 0>;
				strategy_temp_normal_high =	<11000 4230 5000 0 0
								11000 4460 4500 0 0
								11000 4460 4000 0 0
								11000 4460 3500 0 0
								11000 4460 3000 0 0
								11000 4460 2950 0 0
								11000 4460 2500 0 0
								11000 4460 2000 0 0
								11000 4460 1500 0 0
								11000 4470 1000 1 0>;
				strategy_temp_warm =		<11000 4120 2000 0 0
								11000 4120 1500 0 0
								11000 4130 1000 1 0>;
			};
			strategy_soc_range_mid_low {
				strategy_temp_little_cold =	<11000 4140 1750 0 0
								11000 4140 1500 0 0
								11000 4150 1000 1 0>;
				strategy_temp_cool =		<11000 4150 2500 0 0
								11000 4150 2000 0 0
								11000 4480 1750 0 0
								11000 4480 1500 0 0
								11000 4490 1000 1 0>;
				strategy_temp_little_cool =	<11000 4150 3750 0 0
								11000 4150 3500 0 0
								11000 4230 2950 0 0
								11000 4230 2500 0 0
								11000 4230 2000 0 0
								11000 4480 1750 0 0
								11000 4480 1500 0 0
								11000 4490 1000 1 0>;
				strategy_temp_little_cool_high = <11000 4480 4000 0 0
								11000 4480 3500 0 0
								11000 4480 3000 0 0
								11000 4480 2950 0 0
								11000 4480 2500 0 0
								11000 4480 2000 0 0
								11000 4480 1500 0 0
								11000 4490 1000 1 0>;
				strategy_temp_normal_low =	<11000 4230 5000 0 0
								11000 4480 4500 0 0
								11000 4480 4000 0 0
								11000 4480 3500 0 0
								11000 4480 3000 0 0
								11000 4480 2950 0 0
								11000 4480 2500 0 0
								11000 4480 2000 0 0
								11000 4480 1500 0 0
								11000 4490 1000 1 0>;
				strategy_temp_normal_high =	<11000 4230 5000 0 0
								11000 4460 4500 0 0
								11000 4460 4000 0 0
								11000 4460 3500 0 0
								11000 4460 3000 0 0
								11000 4460 2950 0 0
								11000 4460 2500 0 0
								11000 4460 2000 0 0
								11000 4460 1500 0 0
								11000 4470 1000 1 0>;
				strategy_temp_warm =		<11000 4120 2000 0 0
								11000 4120 1500 0 0
								11000 4130 1000 1 0>;
			};
			strategy_soc_range_mid {
				strategy_temp_little_cold =	<11000 4140 1500 0 0
								11000 4150 1000 1 0>;
				strategy_temp_cool =		<11000 4480 1500 0 0
								11000 4490 1000 1 0>;
				strategy_temp_little_cool =	<11000 4230 2500 0 0
								11000 4230 2000 0 0
								11000 4480 1750 0 0
								11000 4480 1500 0 0
								11000 4490 1000 1 0>;
				strategy_temp_little_cool_high = <11000 4480 3000 0 0
								11000 4480 2950 0 0
								11000 4480 2500 0 0
								11000 4480 2000 0 0
								11000 4480 1500 0 0
								11000 4490 1000 1 0>;
				strategy_temp_normal_low =	<11000 4480 3000 0 0
								11000 4480 2950 0 0
								11000 4480 2500 0 0
								11000 4480 2000 0 0
								11000 4480 1500 0 0
								11000 4490 1000 1 0>;
				strategy_temp_normal_high =	<11000 4460 3500 0 0
								11000 4460 3000 0 0
								11000 4460 2950 0 0
								11000 4460 2500 0 0
								11000 4460 2000 0 0
								11000 4460 1500 0 0
								11000 4470 1000 1 0>;
				strategy_temp_warm =		<11000 4130 1000 1 0>;
			};
			strategy_soc_range_mid_high {
				strategy_temp_little_cold =	<11000 4150 1000 1 0>;
				strategy_temp_cool =		<11000 4480 1500 0 0
								11000 4490 1000 1 0>;
				strategy_temp_little_cool =	<11000 4230 2000 0 0
								11000 4480 1750 0 0
								11000 4480 1500 0 0
								11000 4490 1000 1 0>;
				strategy_temp_little_cool_high = <11000 4480 2500 0 0
								11000 4480 2000 0 0
								11000 4480 1500 0 0
								11000 4490 1000 1 0>;
				strategy_temp_normal_low =	<11000 4480 3000 0 0
								11000 4480 2950 0 0
								11000 4480 2500 0 0
								11000 4480 2000 0 0
								11000 4480 1500 0 0
								11000 4490 1000 1 0>;
				strategy_temp_normal_high =	<11000 4460 3000 0 0
								11000 4460 2950 0 0
								11000 4460 2500 0 0
								11000 4460 2000 0 0
								11000 4460 1500 0 0
								11000 4470 1000 1 0>;
				strategy_temp_warm =		<11000 4130 1000 1 0>;
			};
			strategy_soc_range_high {
				strategy_temp_little_cold =	<11000 4150 1000 1 0>;
				strategy_temp_cool =		<11000 4490 1000 1 0>;
				strategy_temp_little_cool =	<11000 4480 1500 0 0
								11000 4490 1000 1 0>;
				strategy_temp_little_cool_high = <11000 4480 2000 0 0
								11000 4480 1500 0 0
								11000 4490 1000 1 0>;
				strategy_temp_normal_low =	<11000 4480 2000 0 0
								11000 4480 1500 0 0
								11000 4490 1000 1 0>;
				strategy_temp_normal_high =	<11000 4460 2500 0 0
								11000 4460 2000 0 0
								11000 4460 1500 0 0
								11000 4470 1000 1 0>;
				strategy_temp_warm =		<11000 4130 1000 1 0>;
			};
		};
	};
};
//#endif OPLUS_FEATURE_CHG_BASIC /*for pps config*/

&soc {
	oplus_chg_plc: oplus,plc_charge {
		compatible = "oplus,plc_charge";
		oplus,plc_soc = <90>;
		oplus,plc_support_timeout;
		oplus,plc_strategy-data = <&buck_simple_strategy>;
		oplus,plc_strategy-names = "default";

		oplus_ufcs_step_strategy: oplus_ufcs_step_strategy {
			oplus,strategy_type = <PLC_STRATEGY_STEP>;
		};

		cp_2t1_simple_strategy: cp_2t1_simple_strategy {
			oplus,strategy_type = <PLC_STRATEGY_SIMPLE>;
			oplus,strategy_data {
				strategy_curr_ma = <1000 1500>;
			};
		};

		cp_1t1_simple_strategy: cp_1t1_simple_strategy {
			oplus,strategy_type = <PLC_STRATEGY_SIMPLE>;
			oplus,strategy_data {
				strategy_curr_ma = <2000 3000>;
			};
		};

		buck_simple_strategy: buck_simple_strategy {
			oplus,strategy_type = <PLC_STRATEGY_SIMPLE>;
		};
	};
};

&tlmm {
	wls_charge_int_active: wls_charge_int_active {
		mux {
			pins = "gpio67";
			function = "gpio";
		};

		config {
			pins = "gpio67";
			bias-pull-up;
			input-enable;
			drive-strength = <2>;
		};
	};

	wls_charge_int_sleep: wls_charge_int_sleep {
		mux {
			pins = "gpio67";
			function = "gpio";
		};

		config {
			pins = "gpio67";
			bias-pull-down;
			input-enable;
			drive-strength = <2>;
		};
	};

	wls_charge_int_default: wls_charge_int_default {
		mux {
			pins = "gpio67";
			function = "gpio";
		};

		config {
			pins = "gpio67";
			bias-pull-down;
			input-enable;
			drive-strength = <2>;
		};
	};

	wls_sleep_active: wls_sleep_active {
		mux {
			pins = "gpio105";
			function = "gpio";
		};

		config {
			pins = "gpio105";
			bias-disable;
			input-disable;
			output-high;
			drive-strength = <2>;
		};
	};

	wls_sleep_sleep: wls_sleep_sleep {
		mux {
			pins = "gpio105";
			function = "gpio";
		};

		config {
			pins = "gpio105";
			bias-disable;
			input-disable;
			output-low;
			drive-strength = <2>;
		};
	};

	wls_sleep_default: wls_sleep_default {
		mux {
			pins = "gpio105";
			function = "gpio";
		};

		config {
			pins = "gpio105";
			bias-disable;
			input-disable;
			output-high;
			drive-strength = <2>;
		};
	};


	wls_scan_active: wls_scan_active {
		mux {
			pins = "gpio106";
			function = "gpio";
		};

		config {
			pins = "gpio106";
			bias-disable;
			input-disable;
			output-high;
			drive-strength = <2>;
		};
	};

	wls_scan_sleep: wls_scan_sleep {
		mux {
			pins = "gpio106";
			function = "gpio";
		};

		config {
			pins = "gpio106";
			bias-disable;
			input-disable;
			output-low;
			drive-strength = <2>;
		};
	};

	wls_scan_default: wls_scan_default {
		mux {
			pins = "gpio106";
			function = "gpio";
		};

		config {
			pins = "gpio106";
			bias-disable;
			input-disable;
			output-high;
			drive-strength = <2>;
		};
	};

	wls_sw_en_active: wls_sw_en_active {
		mux {
			pins = "gpio202";
			function = "gpio";
		};

		config {
			pins = "gpio202";
			bias-disable;
			input-disable;
			output-high;
			drive-strength = <2>;
		};
	};
	wls_sw_en_sleep: wls_sw_en_sleep {
		mux {
			pins = "gpio202";
			function = "gpio";
		};

		config {
			pins = "gpio202";
			bias-disable;
			input-disable;
			output-low;
			drive-strength = <2>;
		};
	};
	wls_sw_en_default: wls_sw_en_default {
		mux {
			pins = "gpio202";
			function = "gpio";
		};

		config {
			pins = "gpio202";
			bias-disable;
			input-disable;
			output-low;
			drive-strength = <2>;
		};
	};

	wls_off_state_active: wls_off_state_active {
		mux {
			pins = "gpio66";
			function = "gpio";
		};

		config {
			pins = "gpio66";
			bias-disable;
			input-disable;
			output-high;
			drive-strength = <2>;
		};
	};
	wls_off_state_sleep: wls_off_state_sleep {
		mux {
			pins = "gpio66";
			function = "gpio";
		};

		config {
			pins = "gpio66";
			bias-disable;
			input-disable;
			output-low;
			drive-strength = <2>;
		};
	};
	wls_off_state_default: wls_off_state_default {
		mux {
			pins = "gpio66";
			function = "gpio";
		};

		config {
			pins = "gpio66";
			bias-disable;
			input-disable;
			output-high;
			drive-strength = <2>;
		};
	};
};

&qupv3_se12_i2c {
	status = "ok";
	pencil-wireless-charger@2b {
		status = "ok";
		compatible = "oplus,wls-tx-mt5806";
		reg = <0x2b 0>;

		pinctrl-names =  "wls_charge_int_active", "wls_charge_int_sleep", "wls_charge_int_default",
		"wls_sleep_active", "wls_sleep_sleep", "wls_sleep_default",
		"wls_scan_active", "wls_scan_sleep", "wls_scan_default",
		"wls_off_state_active", "wls_off_state_sleep", "wls_off_state_default",
		"wls_sw_en_active", "wls_sw_en_sleep", "wls_sw_en_default";

		pinctrl-0 = <&wls_charge_int_active>;
		pinctrl-1 = <&wls_charge_int_sleep>;
		pinctrl-2 = <&wls_charge_int_default>;
		pinctrl-3 = <&wls_sleep_active>;
		pinctrl-4 = <&wls_sleep_sleep>;
		pinctrl-5 = <&wls_sleep_default>;
		pinctrl-6 = <&wls_scan_active>;
		pinctrl-7 = <&wls_scan_sleep>;
		pinctrl-8 = <&wls_scan_default>;
		pinctrl-9 = <&wls_off_state_active>;
		pinctrl-10 = <&wls_off_state_sleep>;
		pinctrl-11 = <&wls_off_state_default>;
		pinctrl-12 = <&wls_sw_en_active>;
		pinctrl-13 = <&wls_sw_en_sleep>;
		pinctrl-14 = <&wls_sw_en_default>;

		wls_int_gpio = <&tlmm 67 0x00>;
		wls_sleep_gpio = <&tlmm 105 0x00>;
		scan_mode_gpio = <&tlmm 106 0x00>;
		wls_off_state_gpio = <&tlmm 66 0x00>;
		wls_sw_en_gpio = <&tlmm 202 0x00>;

		mt_ocp_threshold = <800>;
		mt_ovp_threshold = <9000>;
		mt_fod_threshold = <3000 3300 3800>;
		rx,soc_threshold = <80>;
	};
};
